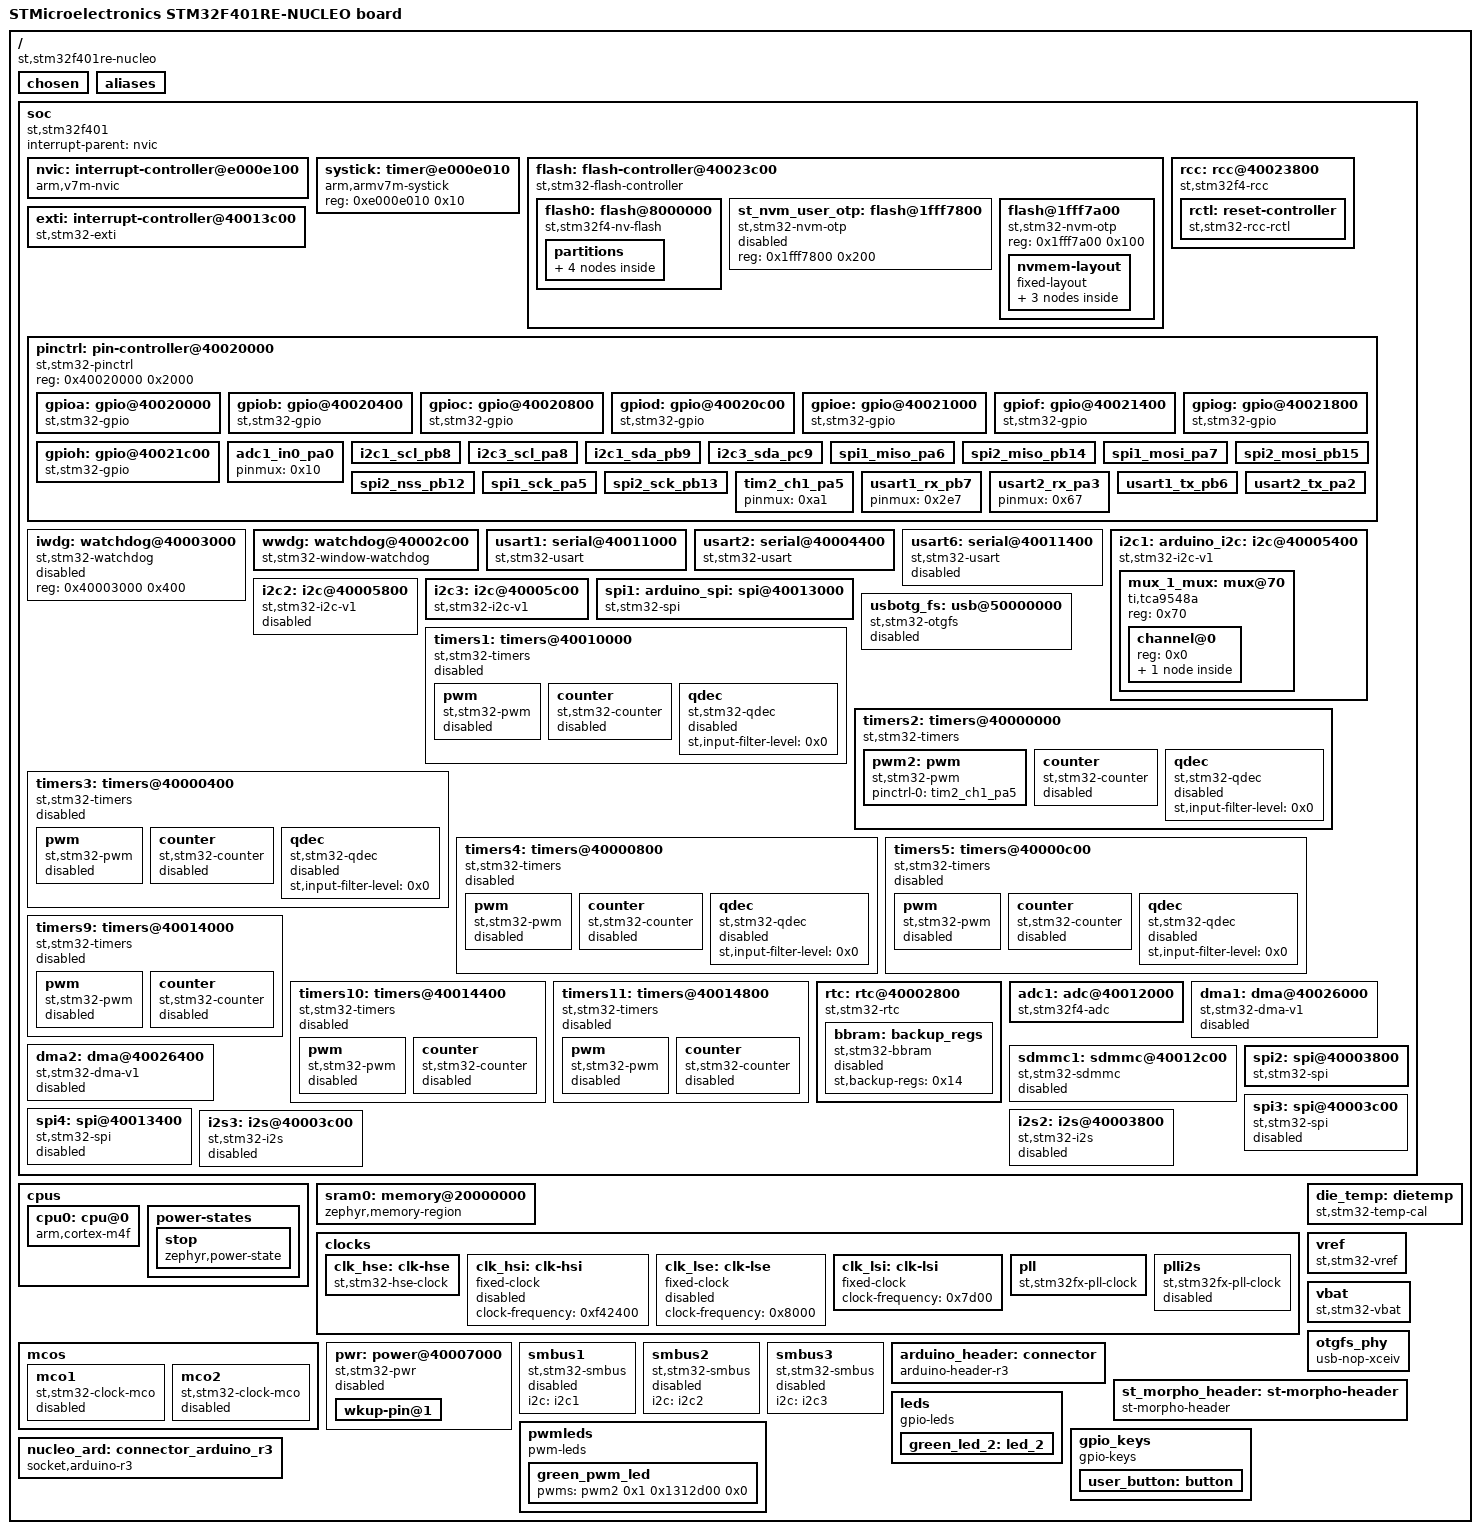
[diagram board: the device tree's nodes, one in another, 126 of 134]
/dts-v1/;

/* node '/' defined in zephyr/dts/common/skeleton.dtsi:9 */
/ {
	#address-cells = < 0x1 >;                              /* in zephyr/dts/common/skeleton.dtsi:10 */
	#size-cells = < 0x1 >;                                 /* in zephyr/dts/common/skeleton.dtsi:11 */
	model = "STMicroelectronics STM32F401RE-NUCLEO board"; /* in zephyr/boards/st/nucleo_f401re/nucleo_f401re.dts:16 */
	compatible = "st,stm32f401re-nucleo";                  /* in zephyr/boards/st/nucleo_f401re/nucleo_f401re.dts:17 */

	/* node '/chosen' defined in zephyr/dts/common/skeleton.dtsi:13 */
	chosen {
		zephyr,flash-controller = &flash;         /* in zephyr/dts/arm/st/f4/stm32f4.dtsi:26 */
		zephyr,system-timer-companion = &rtc;     /* in zephyr/dts/arm/st/f4/stm32f4.dtsi:27 */
		zephyr,console = &usart2;                 /* in zephyr/boards/st/nucleo_f401re/nucleo_f401re.dts:20 */
		zephyr,shell-uart = &usart2;              /* in zephyr/boards/st/nucleo_f401re/nucleo_f401re.dts:21 */
		zephyr,sram = &sram0;                     /* in zephyr/boards/st/nucleo_f401re/nucleo_f401re.dts:22 */
		zephyr,flash = &flash0;                   /* in zephyr/boards/st/nucleo_f401re/nucleo_f401re.dts:23 */
		zephyr,code-partition = &slot0_partition; /* in zephyr/boards/st/nucleo_f401re/nucleo_f401re.dts:24 */
	};

	/* node '/aliases' defined in zephyr/dts/common/skeleton.dtsi:15 */
	aliases {
		led0 = &green_led_2;       /* in zephyr/boards/st/nucleo_f401re/nucleo_f401re.dts:55 */
		sw0 = &user_button;        /* in zephyr/boards/st/nucleo_f401re/nucleo_f401re.dts:56 */
		pwm-led0 = &green_pwm_led; /* in zephyr/boards/st/nucleo_f401re/nucleo_f401re.dts:57 */
		watchdog0 = &wwdg;         /* in zephyr/boards/st/nucleo_f401re/nucleo_f401re.dts:58 */
		die-temp0 = &die_temp;     /* in zephyr/boards/st/nucleo_f401re/nucleo_f401re.dts:59 */
		rtc = &rtc;                /* in zephyr/boards/st/nucleo_f401re/nucleo_f401re.dts:60 */
		volt-sensor0 = &vref;      /* in zephyr/boards/st/nucleo_f401re/nucleo_f401re.dts:61 */
		volt-sensor1 = &vbat;      /* in zephyr/boards/st/nucleo_f401re/nucleo_f401re.dts:62 */
	};

	/* node '/soc' defined in zephyr/dts/arm/armv7-m.dtsi:6 */
	soc {
		#address-cells = < 0x1 >;     /* in zephyr/dts/arm/armv7-m.dtsi:7 */
		#size-cells = < 0x1 >;        /* in zephyr/dts/arm/armv7-m.dtsi:8 */
		interrupt-parent = < &nvic >; /* in zephyr/dts/arm/armv7-m.dtsi:10 */
		ranges;                       /* in zephyr/dts/arm/armv7-m.dtsi:11 */
		compatible = "st,stm32f401",
		             "st,stm32f4",
		             "simple-bus";    /* in zephyr/dts/arm/st/f4/stm32f401.dtsi:19 */

		/* node '/soc/interrupt-controller@e000e100' defined in zephyr/dts/arm/armv7-m.dtsi:13 */
		nvic: interrupt-controller@e000e100 {
			#address-cells = < 0x1 >;            /* in zephyr/dts/arm/armv7-m.dtsi:14 */
			compatible = "arm,v7m-nvic";         /* in zephyr/dts/arm/armv7-m.dtsi:15 */
			reg = < 0xe000e100 0xc00 >;          /* in zephyr/dts/arm/armv7-m.dtsi:16 */
			interrupt-controller;                /* in zephyr/dts/arm/armv7-m.dtsi:17 */
			#interrupt-cells = < 0x2 >;          /* in zephyr/dts/arm/armv7-m.dtsi:18 */
			arm,num-irq-priority-bits = < 0x4 >; /* in zephyr/dts/arm/st/f4/stm32f4.dtsi:730 */
			phandle = < 0x1 >;                   /* in zephyr/dts/arm/armv7-m.dtsi:10 */
		};

		/* node '/soc/timer@e000e010' defined in zephyr/dts/arm/armv7-m.dtsi:21 */
		systick: timer@e000e010 {
			compatible = "arm,armv7m-systick"; /* in zephyr/dts/arm/armv7-m.dtsi:22 */
			reg = < 0xe000e010 0x10 >;         /* in zephyr/dts/arm/armv7-m.dtsi:23 */
		};

		/* node '/soc/flash-controller@40023c00' defined in zephyr/dts/arm/st/f4/stm32f4.dtsi:112 */
		flash: flash-controller@40023c00 {
			compatible = "st,stm32-flash-controller",
			             "st,stm32f4-flash-controller"; /* in zephyr/dts/arm/st/f4/stm32f4.dtsi:113 */
			reg = < 0x40023c00 0x400 >;                 /* in zephyr/dts/arm/st/f4/stm32f4.dtsi:114 */
			interrupts = < 0x4 0x0 >;                   /* in zephyr/dts/arm/st/f4/stm32f4.dtsi:115 */
			#address-cells = < 0x1 >;                   /* in zephyr/dts/arm/st/f4/stm32f4.dtsi:117 */
			#size-cells = < 0x1 >;                      /* in zephyr/dts/arm/st/f4/stm32f4.dtsi:118 */
			ranges;                                     /* in zephyr/dts/arm/st/f4/stm32f4.dtsi:119 */

			/* node '/soc/flash-controller@40023c00/flash@8000000' defined in zephyr/dts/arm/st/f4/stm32f4.dtsi:121 */
			flash0: flash@8000000 {
				compatible = "st,stm32f4-nv-flash",
				             "st,stm32-nv-flash",
				             "soc-nv-flash";        /* in zephyr/dts/arm/st/f4/stm32f4.dtsi:122 */
				#address-cells = < 0x1 >;           /* in zephyr/dts/arm/st/f4/stm32f4.dtsi:124 */
				#size-cells = < 0x1 >;              /* in zephyr/dts/arm/st/f4/stm32f4.dtsi:125 */
				write-block-size = < 0x1 >;         /* in zephyr/dts/arm/st/f4/stm32f4.dtsi:126 */
				max-erase-time = < 0xfa0 >;         /* in zephyr/dts/arm/st/f4/stm32f4.dtsi:128 */
				reg = < 0x8000000 0x80000 >;        /* in zephyr/dts/arm/st/f4/stm32f401Xe.dtsi:17 */
				ranges = < 0x0 0x8000000 0x80000 >; /* in zephyr/dts/arm/st/f4/stm32f401Xe.dtsi:18 */

				/* node '/soc/flash-controller@40023c00/flash@8000000/partitions' defined in zephyr/boards/st/nucleo_f401re/nucleo_f401re.dts:140 */
				partitions {
					#address-cells = < 0x1 >; /* in zephyr/boards/st/nucleo_f401re/nucleo_f401re.dts:141 */
					#size-cells = < 0x1 >;    /* in zephyr/boards/st/nucleo_f401re/nucleo_f401re.dts:142 */
					ranges;                   /* in zephyr/boards/st/nucleo_f401re/nucleo_f401re.dts:143 */

					/* node '/soc/flash-controller@40023c00/flash@8000000/partitions/partition@0' defined in zephyr/boards/st/nucleo_f401re/nucleo_f401re.dts:145 */
					boot_partition: partition@0 {
						compatible = "zephyr,mapped-partition"; /* in zephyr/boards/st/nucleo_f401re/nucleo_f401re.dts:146 */
						label = "mcuboot";                      /* in zephyr/boards/st/nucleo_f401re/nucleo_f401re.dts:147 */
						reg = < 0x0 0x10000 >;                  /* in zephyr/boards/st/nucleo_f401re/nucleo_f401re.dts:148 */
						read-only;                              /* in zephyr/boards/st/nucleo_f401re/nucleo_f401re.dts:149 */
					};

					/* node '/soc/flash-controller@40023c00/flash@8000000/partitions/partition@20000' defined in zephyr/boards/st/nucleo_f401re/nucleo_f401re.dts:157 */
					slot0_partition: partition@20000 {
						compatible = "zephyr,mapped-partition"; /* in zephyr/boards/st/nucleo_f401re/nucleo_f401re.dts:158 */
						label = "image-0";                      /* in zephyr/boards/st/nucleo_f401re/nucleo_f401re.dts:159 */
						reg = < 0x20000 0x20000 >;              /* in zephyr/boards/st/nucleo_f401re/nucleo_f401re.dts:160 */
					};

					/* node '/soc/flash-controller@40023c00/flash@8000000/partitions/partition@40000' defined in zephyr/boards/st/nucleo_f401re/nucleo_f401re.dts:163 */
					slot1_partition: partition@40000 {
						compatible = "zephyr,mapped-partition"; /* in zephyr/boards/st/nucleo_f401re/nucleo_f401re.dts:164 */
						label = "image-1";                      /* in zephyr/boards/st/nucleo_f401re/nucleo_f401re.dts:165 */
						reg = < 0x40000 0x20000 >;              /* in zephyr/boards/st/nucleo_f401re/nucleo_f401re.dts:166 */
					};

					/* node '/soc/flash-controller@40023c00/flash@8000000/partitions/partition@60000' defined in zephyr/boards/st/nucleo_f401re/nucleo_f401re.dts:169 */
					scratch_partition: partition@60000 {
						compatible = "zephyr,mapped-partition"; /* in zephyr/boards/st/nucleo_f401re/nucleo_f401re.dts:170 */
						label = "image-scratch";                /* in zephyr/boards/st/nucleo_f401re/nucleo_f401re.dts:171 */
						reg = < 0x60000 0x20000 >;              /* in zephyr/boards/st/nucleo_f401re/nucleo_f401re.dts:172 */
					};
				};
			};

			/* node '/soc/flash-controller@40023c00/flash@1fff7800' defined in zephyr/dts/arm/st/f4/stm32f4.dtsi:131 */
			st_nvm_user_otp: flash@1fff7800 {
				compatible = "st,stm32-nvm-otp"; /* in zephyr/dts/arm/st/f4/stm32f4.dtsi:132 */
				reg = < 0x1fff7800 0x200 >;      /* in zephyr/dts/arm/st/f4/stm32f4.dtsi:133 */
				status = "disabled";             /* in zephyr/dts/arm/st/f4/stm32f4.dtsi:134 */
			};

			/* node '/soc/flash-controller@40023c00/flash@1fff7a00' defined in zephyr/dts/arm/st/f4/stm32f4.dtsi:148 */
			flash@1fff7a00 {
				compatible = "st,stm32-nvm-otp"; /* in zephyr/dts/arm/st/f4/stm32f4.dtsi:149 */
				reg = < 0x1fff7a00 0x100 >;      /* in zephyr/dts/arm/st/f4/stm32f4.dtsi:150 */

				/* node '/soc/flash-controller@40023c00/flash@1fff7a00/nvmem-layout' defined in zephyr/dts/arm/st/f4/stm32f4.dtsi:152 */
				nvmem-layout {
					compatible = "fixed-layout"; /* in zephyr/dts/arm/st/f4/stm32f4.dtsi:153 */
					#address-cells = < 0x1 >;    /* in zephyr/dts/arm/st/f4/stm32f4.dtsi:154 */
					#size-cells = < 0x1 >;       /* in zephyr/dts/arm/st/f4/stm32f4.dtsi:155 */

					/* node '/soc/flash-controller@40023c00/flash@1fff7a00/nvmem-layout/vrefint@2a' defined in zephyr/dts/arm/st/f4/stm32f4.dtsi:157 */
					vrefint_otp: vrefint@2a {
						reg = < 0x2a 0x2 >;          /* in zephyr/dts/arm/st/f4/stm32f4.dtsi:158 */
						#nvmem-cell-cells = < 0x0 >; /* in zephyr/dts/arm/st/f4/stm32f4.dtsi:159 */
						read-only;                   /* in zephyr/dts/arm/st/f4/stm32f4.dtsi:160 */
						phandle = < 0x20 >;          /* in zephyr/dts/arm/st/f4/stm32f4.dtsi:686 */
					};

					/* node '/soc/flash-controller@40023c00/flash@1fff7a00/nvmem-layout/ts-cal1@2c' defined in zephyr/dts/arm/st/f4/stm32f4.dtsi:163 */
					ts_cal1_otp: ts-cal1@2c {
						reg = < 0x2c 0x2 >;          /* in zephyr/dts/arm/st/f4/stm32f4.dtsi:164 */
						#nvmem-cell-cells = < 0x0 >; /* in zephyr/dts/arm/st/f4/stm32f4.dtsi:165 */
						read-only;                   /* in zephyr/dts/arm/st/f4/stm32f4.dtsi:166 */
						phandle = < 0x1d >;          /* in zephyr/dts/arm/st/f4/stm32f4.dtsi:675 */
					};

					/* node '/soc/flash-controller@40023c00/flash@1fff7a00/nvmem-layout/ts-cal2@2e' defined in zephyr/dts/arm/st/f4/stm32f4.dtsi:169 */
					ts_cal2_otp: ts-cal2@2e {
						reg = < 0x2e 0x2 >;          /* in zephyr/dts/arm/st/f4/stm32f4.dtsi:170 */
						#nvmem-cell-cells = < 0x0 >; /* in zephyr/dts/arm/st/f4/stm32f4.dtsi:171 */
						read-only;                   /* in zephyr/dts/arm/st/f4/stm32f4.dtsi:172 */
						phandle = < 0x1e >;          /* in zephyr/dts/arm/st/f4/stm32f4.dtsi:675 */
					};
				};
			};
		};

		/* node '/soc/rcc@40023800' defined in zephyr/dts/arm/st/f4/stm32f4.dtsi:178 */
		rcc: rcc@40023800 {
			compatible = "st,stm32f4-rcc";   /* in zephyr/dts/arm/st/f4/stm32f4.dtsi:179 */
			#clock-cells = < 0x2 >;          /* in zephyr/dts/arm/st/f4/stm32f4.dtsi:180 */
			reg = < 0x40023800 0x400 >;      /* in zephyr/dts/arm/st/f4/stm32f4.dtsi:181 */
			clocks = < &pll >;               /* in zephyr/boards/st/nucleo_f401re/nucleo_f401re.dts:86 */
			clock-frequency = < 0x501bd00 >; /* in zephyr/boards/st/nucleo_f401re/nucleo_f401re.dts:87 */
			ahb-prescaler = < 0x1 >;         /* in zephyr/boards/st/nucleo_f401re/nucleo_f401re.dts:88 */
			apb1-prescaler = < 0x2 >;        /* in zephyr/boards/st/nucleo_f401re/nucleo_f401re.dts:89 */
			apb2-prescaler = < 0x1 >;        /* in zephyr/boards/st/nucleo_f401re/nucleo_f401re.dts:90 */
			phandle = < 0x3 >;               /* in zephyr/dts/arm/st/f4/stm32f4.dtsi:195 */

			/* node '/soc/rcc@40023800/reset-controller' defined in zephyr/dts/arm/st/f4/stm32f4.dtsi:183 */
			rctl: reset-controller {
				compatible = "st,stm32-rcc-rctl"; /* in zephyr/dts/arm/st/f4/stm32f4.dtsi:184 */
				#reset-cells = < 0x1 >;           /* in zephyr/dts/arm/st/f4/stm32f4.dtsi:185 */
				phandle = < 0x4 >;                /* in zephyr/dts/arm/st/f4/stm32f4.dtsi:295 */
			};
		};

		/* node '/soc/interrupt-controller@40013c00' defined in zephyr/dts/arm/st/f4/stm32f4.dtsi:189 */
		exti: interrupt-controller@40013c00 {
			compatible = "st,stm32-exti";  /* in zephyr/dts/arm/st/f4/stm32f4.dtsi:190 */
			interrupt-controller;          /* in zephyr/dts/arm/st/f4/stm32f4.dtsi:191 */
			#interrupt-cells = < 0x1 >;    /* in zephyr/dts/arm/st/f4/stm32f4.dtsi:192 */
			#address-cells = < 0x0 >;      /* in zephyr/dts/arm/st/f4/stm32f4.dtsi:193 */
			reg = < 0x40013c00 0x400 >;    /* in zephyr/dts/arm/st/f4/stm32f4.dtsi:194 */
			clocks = < &rcc 0x44 0x4000 >; /* in zephyr/dts/arm/st/f4/stm32f4.dtsi:195 */
			num-lines = < 0x20 >;          /* in zephyr/dts/arm/st/f4/stm32f4.dtsi:196 */
			interrupts = < 0x6 0x0 >,
			             < 0x7 0x0 >,
			             < 0x8 0x0 >,
			             < 0x9 0x0 >,
			             < 0xa 0x0 >,
			             < 0x17 0x0 >,
			             < 0x28 0x0 >;     /* in zephyr/dts/arm/st/f4/stm32f4.dtsi:197 */
			interrupt-names = "line0",
			                  "line1",
			                  "line2",
			                  "line3",
			                  "line4",
			                  "line5-9",
			                  "line10-15"; /* in zephyr/dts/arm/st/f4/stm32f4.dtsi:199 */
			line-ranges = < 0x0 0x1 >,
			              < 0x1 0x1 >,
			              < 0x2 0x1 >,
			              < 0x3 0x1 >,
			              < 0x4 0x1 >,
			              < 0x5 0x5 >,
			              < 0xa 0x6 >;     /* in zephyr/dts/arm/st/f4/stm32f4.dtsi:201 */
		};

		/* node '/soc/pin-controller@40020000' defined in zephyr/dts/arm/st/f4/stm32f4.dtsi:205 */
		pinctrl: pin-controller@40020000 {
			compatible = "st,stm32-pinctrl"; /* in zephyr/dts/arm/st/f4/stm32f4.dtsi:206 */
			#address-cells = < 0x1 >;        /* in zephyr/dts/arm/st/f4/stm32f4.dtsi:207 */
			#size-cells = < 0x1 >;           /* in zephyr/dts/arm/st/f4/stm32f4.dtsi:208 */
			reg = < 0x40020000 0x2000 >;     /* in zephyr/dts/arm/st/f4/stm32f4.dtsi:209 */
			ranges;                          /* in zephyr/dts/arm/st/f4/stm32f4.dtsi:210 */

			/* node '/soc/pin-controller@40020000/gpio@40020000' defined in zephyr/dts/arm/st/f4/stm32f4.dtsi:212 */
			gpioa: gpio@40020000 {
				compatible = "st,stm32-gpio"; /* in zephyr/dts/arm/st/f4/stm32f4.dtsi:213 */
				gpio-controller;              /* in zephyr/dts/arm/st/f4/stm32f4.dtsi:214 */
				#gpio-cells = < 0x2 >;        /* in zephyr/dts/arm/st/f4/stm32f4.dtsi:215 */
				reg = < 0x40020000 0x400 >;   /* in zephyr/dts/arm/st/f4/stm32f4.dtsi:216 */
				clocks = < &rcc 0x30 0x1 >;   /* in zephyr/dts/arm/st/f4/stm32f4.dtsi:217 */
				phandle = < 0xe >;            /* in zephyr/boards/st/nucleo_f401re/nucleo_f401re.dts:119 */
			};

			/* node '/soc/pin-controller@40020000/gpio@40020400' defined in zephyr/dts/arm/st/f4/stm32f4.dtsi:220 */
			gpiob: gpio@40020400 {
				compatible = "st,stm32-gpio"; /* in zephyr/dts/arm/st/f4/stm32f4.dtsi:221 */
				gpio-controller;              /* in zephyr/dts/arm/st/f4/stm32f4.dtsi:222 */
				#gpio-cells = < 0x2 >;        /* in zephyr/dts/arm/st/f4/stm32f4.dtsi:223 */
				reg = < 0x40020400 0x400 >;   /* in zephyr/dts/arm/st/f4/stm32f4.dtsi:224 */
				clocks = < &rcc 0x30 0x2 >;   /* in zephyr/dts/arm/st/f4/stm32f4.dtsi:225 */
				phandle = < 0xb >;            /* in zephyr/boards/st/nucleo_f401re/nucleo_f401re.dts:110 */
			};

			/* node '/soc/pin-controller@40020000/gpio@40020800' defined in zephyr/dts/arm/st/f4/stm32f4.dtsi:228 */
			gpioc: gpio@40020800 {
				compatible = "st,stm32-gpio"; /* in zephyr/dts/arm/st/f4/stm32f4.dtsi:229 */
				gpio-controller;              /* in zephyr/dts/arm/st/f4/stm32f4.dtsi:230 */
				#gpio-cells = < 0x2 >;        /* in zephyr/dts/arm/st/f4/stm32f4.dtsi:231 */
				reg = < 0x40020800 0x400 >;   /* in zephyr/dts/arm/st/f4/stm32f4.dtsi:232 */
				clocks = < &rcc 0x30 0x4 >;   /* in zephyr/dts/arm/st/f4/stm32f4.dtsi:233 */
				phandle = < 0xf >;            /* in zephyr/boards/st/nucleo_f401re/nucleo_f401re.dts:120 */
			};

			/* node '/soc/pin-controller@40020000/gpio@40020c00' defined in zephyr/dts/arm/st/f4/stm32f4.dtsi:236 */
			gpiod: gpio@40020c00 {
				compatible = "st,stm32-gpio"; /* in zephyr/dts/arm/st/f4/stm32f4.dtsi:237 */
				gpio-controller;              /* in zephyr/dts/arm/st/f4/stm32f4.dtsi:238 */
				#gpio-cells = < 0x2 >;        /* in zephyr/dts/arm/st/f4/stm32f4.dtsi:239 */
				reg = < 0x40020c00 0x400 >;   /* in zephyr/dts/arm/st/f4/stm32f4.dtsi:240 */
				clocks = < &rcc 0x30 0x8 >;   /* in zephyr/dts/arm/st/f4/stm32f4.dtsi:241 */
				phandle = < 0x24 >;           /* in zephyr/boards/st/nucleo_f401re/st_morpho_connector.dtsi:15 */
			};

			/* node '/soc/pin-controller@40020000/gpio@40021000' defined in zephyr/dts/arm/st/f4/stm32f4.dtsi:244 */
			gpioe: gpio@40021000 {
				compatible = "st,stm32-gpio"; /* in zephyr/dts/arm/st/f4/stm32f4.dtsi:245 */
				gpio-controller;              /* in zephyr/dts/arm/st/f4/stm32f4.dtsi:246 */
				#gpio-cells = < 0x2 >;        /* in zephyr/dts/arm/st/f4/stm32f4.dtsi:247 */
				reg = < 0x40021000 0x400 >;   /* in zephyr/dts/arm/st/f4/stm32f4.dtsi:248 */
				clocks = < &rcc 0x30 0x10 >;  /* in zephyr/dts/arm/st/f4/stm32f4.dtsi:249 */
			};

			/* node '/soc/pin-controller@40020000/gpio@40021400' defined in zephyr/dts/arm/st/f4/stm32f4.dtsi:252 */
			gpiof: gpio@40021400 {
				compatible = "st,stm32-gpio"; /* in zephyr/dts/arm/st/f4/stm32f4.dtsi:253 */
				gpio-controller;              /* in zephyr/dts/arm/st/f4/stm32f4.dtsi:254 */
				#gpio-cells = < 0x2 >;        /* in zephyr/dts/arm/st/f4/stm32f4.dtsi:255 */
				reg = < 0x40021400 0x400 >;   /* in zephyr/dts/arm/st/f4/stm32f4.dtsi:256 */
				clocks = < &rcc 0x30 0x20 >;  /* in zephyr/dts/arm/st/f4/stm32f4.dtsi:257 */
			};

			/* node '/soc/pin-controller@40020000/gpio@40021800' defined in zephyr/dts/arm/st/f4/stm32f4.dtsi:260 */
			gpiog: gpio@40021800 {
				compatible = "st,stm32-gpio"; /* in zephyr/dts/arm/st/f4/stm32f4.dtsi:261 */
				gpio-controller;              /* in zephyr/dts/arm/st/f4/stm32f4.dtsi:262 */
				#gpio-cells = < 0x2 >;        /* in zephyr/dts/arm/st/f4/stm32f4.dtsi:263 */
				reg = < 0x40021800 0x400 >;   /* in zephyr/dts/arm/st/f4/stm32f4.dtsi:264 */
				clocks = < &rcc 0x30 0x40 >;  /* in zephyr/dts/arm/st/f4/stm32f4.dtsi:265 */
			};

			/* node '/soc/pin-controller@40020000/gpio@40021c00' defined in zephyr/dts/arm/st/f4/stm32f4.dtsi:268 */
			gpioh: gpio@40021c00 {
				compatible = "st,stm32-gpio"; /* in zephyr/dts/arm/st/f4/stm32f4.dtsi:269 */
				gpio-controller;              /* in zephyr/dts/arm/st/f4/stm32f4.dtsi:270 */
				#gpio-cells = < 0x2 >;        /* in zephyr/dts/arm/st/f4/stm32f4.dtsi:271 */
				reg = < 0x40021c00 0x400 >;   /* in zephyr/dts/arm/st/f4/stm32f4.dtsi:272 */
				clocks = < &rcc 0x30 0x80 >;  /* in zephyr/dts/arm/st/f4/stm32f4.dtsi:273 */
				phandle = < 0x25 >;           /* in zephyr/boards/st/nucleo_f401re/st_morpho_connector.dtsi:15 */
			};

			/* node '/soc/pin-controller@40020000/adc1_in0_pa0' defined in modules/hal/stm32/dts/st/f4/stm32f401r(d-e)tx-pinctrl.dtsi:13 */
			adc1_in0_pa0: adc1_in0_pa0 {
				pinmux = < 0x10 >;  /* in modules/hal/stm32/dts/st/f4/stm32f401r(d-e)tx-pinctrl.dtsi:14 */
				phandle = < 0x15 >; /* in zephyr/boards/st/nucleo_f401re/nucleo_f401re.dts:194 */
			};

			/* node '/soc/pin-controller@40020000/i2c1_scl_pb8' defined in modules/hal/stm32/dts/st/f4/stm32f401r(d-e)tx-pinctrl.dtsi:287 */
			i2c1_scl_pb8: i2c1_scl_pb8 {
				pinmux = < 0x304 >; /* in modules/hal/stm32/dts/st/f4/stm32f401r(d-e)tx-pinctrl.dtsi:288 */
				bias-pull-up;       /* in modules/hal/stm32/dts/st/f4/stm32f401r(d-e)tx-pinctrl.dtsi:289 */
				drive-open-drain;   /* in modules/hal/stm32/dts/st/f4/stm32f401r(d-e)tx-pinctrl.dtsi:290 */
				phandle = < 0x9 >;  /* in zephyr/boards/st/nucleo_f401re/nucleo_f401re.dts:108 */
			};

			/* node '/soc/pin-controller@40020000/i2c3_scl_pa8' defined in modules/hal/stm32/dts/st/f4/stm32f401r(d-e)tx-pinctrl.dtsi:299 */
			i2c3_scl_pa8: i2c3_scl_pa8 {
				pinmux = < 0x104 >; /* in modules/hal/stm32/dts/st/f4/stm32f401r(d-e)tx-pinctrl.dtsi:300 */
				bias-pull-up;       /* in modules/hal/stm32/dts/st/f4/stm32f401r(d-e)tx-pinctrl.dtsi:301 */
				drive-open-drain;   /* in modules/hal/stm32/dts/st/f4/stm32f401r(d-e)tx-pinctrl.dtsi:302 */
				phandle = < 0xc >;  /* in zephyr/boards/st/nucleo_f401re/nucleo_f401re.dts:117 */
			};

			/* node '/soc/pin-controller@40020000/i2c1_sda_pb9' defined in modules/hal/stm32/dts/st/f4/stm32f401r(d-e)tx-pinctrl.dtsi:313 */
			i2c1_sda_pb9: i2c1_sda_pb9 {
				pinmux = < 0x324 >; /* in modules/hal/stm32/dts/st/f4/stm32f401r(d-e)tx-pinctrl.dtsi:314 */
				bias-pull-up;       /* in modules/hal/stm32/dts/st/f4/stm32f401r(d-e)tx-pinctrl.dtsi:315 */
				drive-open-drain;   /* in modules/hal/stm32/dts/st/f4/stm32f401r(d-e)tx-pinctrl.dtsi:316 */
				phandle = < 0xa >;  /* in zephyr/boards/st/nucleo_f401re/nucleo_f401re.dts:108 */
			};

			/* node '/soc/pin-controller@40020000/i2c3_sda_pc9' defined in modules/hal/stm32/dts/st/f4/stm32f401r(d-e)tx-pinctrl.dtsi:331 */
			i2c3_sda_pc9: i2c3_sda_pc9 {
				pinmux = < 0x524 >; /* in modules/hal/stm32/dts/st/f4/stm32f401r(d-e)tx-pinctrl.dtsi:332 */
				bias-pull-up;       /* in modules/hal/stm32/dts/st/f4/stm32f401r(d-e)tx-pinctrl.dtsi:333 */
				drive-open-drain;   /* in modules/hal/stm32/dts/st/f4/stm32f401r(d-e)tx-pinctrl.dtsi:334 */
				phandle = < 0xd >;  /* in zephyr/boards/st/nucleo_f401re/nucleo_f401re.dts:117 */
			};

			/* node '/soc/pin-controller@40020000/spi1_miso_pa6' defined in modules/hal/stm32/dts/st/f4/stm32f401r(d-e)tx-pinctrl.dtsi:522 */
			spi1_miso_pa6: spi1_miso_pa6 {
				pinmux = < 0xc5 >;             /* in modules/hal/stm32/dts/st/f4/stm32f401r(d-e)tx-pinctrl.dtsi:523 */
				bias-pull-down;                /* in modules/hal/stm32/dts/st/f4/stm32f401r(d-e)tx-pinctrl.dtsi:524 */
				slew-rate = "very-high-speed"; /* in modules/hal/stm32/dts/st/f4/stm32f401r(d-e)tx-pinctrl.dtsi:525 */
				phandle = < 0x11 >;            /* in zephyr/boards/st/nucleo_f401re/nucleo_f401re.dts:126 */
			};

			/* node '/soc/pin-controller@40020000/spi2_miso_pb14' defined in modules/hal/stm32/dts/st/f4/stm32f401r(d-e)tx-pinctrl.dtsi:534 */
			spi2_miso_pb14: spi2_miso_pb14 {
				pinmux = < 0x3c5 >;            /* in modules/hal/stm32/dts/st/f4/stm32f401r(d-e)tx-pinctrl.dtsi:535 */
				bias-pull-down;                /* in modules/hal/stm32/dts/st/f4/stm32f401r(d-e)tx-pinctrl.dtsi:536 */
				slew-rate = "very-high-speed"; /* in modules/hal/stm32/dts/st/f4/stm32f401r(d-e)tx-pinctrl.dtsi:537 */
				phandle = < 0x18 >;            /* in zephyr/boards/st/nucleo_f401re/nucleo_f401re.dts:133 */
			};

			/* node '/soc/pin-controller@40020000/spi1_mosi_pa7' defined in modules/hal/stm32/dts/st/f4/stm32f401r(d-e)tx-pinctrl.dtsi:560 */
			spi1_mosi_pa7: spi1_mosi_pa7 {
				pinmux = < 0xe5 >;             /* in modules/hal/stm32/dts/st/f4/stm32f401r(d-e)tx-pinctrl.dtsi:561 */
				bias-pull-down;                /* in modules/hal/stm32/dts/st/f4/stm32f401r(d-e)tx-pinctrl.dtsi:562 */
				slew-rate = "very-high-speed"; /* in modules/hal/stm32/dts/st/f4/stm32f401r(d-e)tx-pinctrl.dtsi:563 */
				phandle = < 0x12 >;            /* in zephyr/boards/st/nucleo_f401re/nucleo_f401re.dts:126 */
			};

			/* node '/soc/pin-controller@40020000/spi2_mosi_pb15' defined in modules/hal/stm32/dts/st/f4/stm32f401r(d-e)tx-pinctrl.dtsi:572 */
			spi2_mosi_pb15: spi2_mosi_pb15 {
				pinmux = < 0x3e5 >;            /* in modules/hal/stm32/dts/st/f4/stm32f401r(d-e)tx-pinctrl.dtsi:573 */
				bias-pull-down;                /* in modules/hal/stm32/dts/st/f4/stm32f401r(d-e)tx-pinctrl.dtsi:574 */
				slew-rate = "very-high-speed"; /* in modules/hal/stm32/dts/st/f4/stm32f401r(d-e)tx-pinctrl.dtsi:575 */
				phandle = < 0x19 >;            /* in zephyr/boards/st/nucleo_f401re/nucleo_f401re.dts:133 */
			};

			/* node '/soc/pin-controller@40020000/spi2_nss_pb12' defined in modules/hal/stm32/dts/st/f4/stm32f401r(d-e)tx-pinctrl.dtsi:616 */
			spi2_nss_pb12: spi2_nss_pb12 {
				pinmux = < 0x385 >;            /* in modules/hal/stm32/dts/st/f4/stm32f401r(d-e)tx-pinctrl.dtsi:617 */
				bias-pull-up;                  /* in modules/hal/stm32/dts/st/f4/stm32f401r(d-e)tx-pinctrl.dtsi:618 */
				slew-rate = "very-high-speed"; /* in modules/hal/stm32/dts/st/f4/stm32f401r(d-e)tx-pinctrl.dtsi:619 */
				phandle = < 0x16 >;            /* in zephyr/boards/st/nucleo_f401re/nucleo_f401re.dts:133 */
			};

			/* node '/soc/pin-controller@40020000/spi1_sck_pa5' defined in modules/hal/stm32/dts/st/f4/stm32f401r(d-e)tx-pinctrl.dtsi:636 */
			spi1_sck_pa5: spi1_sck_pa5 {
				pinmux = < 0xa5 >;             /* in modules/hal/stm32/dts/st/f4/stm32f401r(d-e)tx-pinctrl.dtsi:637 */
				bias-pull-down;                /* in modules/hal/stm32/dts/st/f4/stm32f401r(d-e)tx-pinctrl.dtsi:638 */
				slew-rate = "very-high-speed"; /* in modules/hal/stm32/dts/st/f4/stm32f401r(d-e)tx-pinctrl.dtsi:639 */
				phandle = < 0x10 >;            /* in zephyr/boards/st/nucleo_f401re/nucleo_f401re.dts:126 */
			};

			/* node '/soc/pin-controller@40020000/spi2_sck_pb13' defined in modules/hal/stm32/dts/st/f4/stm32f401r(d-e)tx-pinctrl.dtsi:654 */
			spi2_sck_pb13: spi2_sck_pb13 {
				pinmux = < 0x3a5 >;            /* in modules/hal/stm32/dts/st/f4/stm32f401r(d-e)tx-pinctrl.dtsi:655 */
				bias-pull-down;                /* in modules/hal/stm32/dts/st/f4/stm32f401r(d-e)tx-pinctrl.dtsi:656 */
				slew-rate = "very-high-speed"; /* in modules/hal/stm32/dts/st/f4/stm32f401r(d-e)tx-pinctrl.dtsi:657 */
				phandle = < 0x17 >;            /* in zephyr/boards/st/nucleo_f401re/nucleo_f401re.dts:133 */
			};

			/* node '/soc/pin-controller@40020000/tim2_ch1_pa5' defined in modules/hal/stm32/dts/st/f4/stm32f401r(d-e)tx-pinctrl.dtsi:748 */
			tim2_ch1_pa5: tim2_ch1_pa5 {
				pinmux = < 0xa1 >;  /* in modules/hal/stm32/dts/st/f4/stm32f401r(d-e)tx-pinctrl.dtsi:749 */
				phandle = < 0x14 >; /* in zephyr/boards/st/nucleo_f401re/nucleo_f401re.dts:182 */
			};

			/* node '/soc/pin-controller@40020000/usart1_rx_pb7' defined in modules/hal/stm32/dts/st/f4/stm32f401r(d-e)tx-pinctrl.dtsi:874 */
			usart1_rx_pb7: usart1_rx_pb7 {
				pinmux = < 0x2e7 >; /* in modules/hal/stm32/dts/st/f4/stm32f401r(d-e)tx-pinctrl.dtsi:875 */
				phandle = < 0x6 >;  /* in zephyr/boards/st/nucleo_f401re/nucleo_f401re.dts:94 */
			};

			/* node '/soc/pin-controller@40020000/usart2_rx_pa3' defined in modules/hal/stm32/dts/st/f4/stm32f401r(d-e)tx-pinctrl.dtsi:878 */
			usart2_rx_pa3: usart2_rx_pa3 {
				pinmux = < 0x67 >; /* in modules/hal/stm32/dts/st/f4/stm32f401r(d-e)tx-pinctrl.dtsi:879 */
				phandle = < 0x8 >; /* in zephyr/boards/st/nucleo_f401re/nucleo_f401re.dts:101 */
			};

			/* node '/soc/pin-controller@40020000/usart1_tx_pb6' defined in modules/hal/stm32/dts/st/f4/stm32f401r(d-e)tx-pinctrl.dtsi:897 */
			usart1_tx_pb6: usart1_tx_pb6 {
				pinmux = < 0x2c7 >; /* in modules/hal/stm32/dts/st/f4/stm32f401r(d-e)tx-pinctrl.dtsi:898 */
				bias-pull-up;       /* in modules/hal/stm32/dts/st/f4/stm32f401r(d-e)tx-pinctrl.dtsi:899 */
				phandle = < 0x5 >;  /* in zephyr/boards/st/nucleo_f401re/nucleo_f401re.dts:94 */
			};

			/* node '/soc/pin-controller@40020000/usart2_tx_pa2' defined in modules/hal/stm32/dts/st/f4/stm32f401r(d-e)tx-pinctrl.dtsi:902 */
			usart2_tx_pa2: usart2_tx_pa2 {
				pinmux = < 0x47 >; /* in modules/hal/stm32/dts/st/f4/stm32f401r(d-e)tx-pinctrl.dtsi:903 */
				bias-pull-up;      /* in modules/hal/stm32/dts/st/f4/stm32f401r(d-e)tx-pinctrl.dtsi:904 */
				phandle = < 0x7 >; /* in zephyr/boards/st/nucleo_f401re/nucleo_f401re.dts:101 */
			};
		};

		/* node '/soc/watchdog@40003000' defined in zephyr/dts/arm/st/f4/stm32f4.dtsi:277 */
		iwdg: watchdog@40003000 {
			compatible = "st,stm32-watchdog"; /* in zephyr/dts/arm/st/f4/stm32f4.dtsi:278 */
			reg = < 0x40003000 0x400 >;       /* in zephyr/dts/arm/st/f4/stm32f4.dtsi:279 */
			status = "disabled";              /* in zephyr/dts/arm/st/f4/stm32f4.dtsi:280 */
		};

		/* node '/soc/watchdog@40002c00' defined in zephyr/dts/arm/st/f4/stm32f4.dtsi:283 */
		wwdg: watchdog@40002c00 {
			compatible = "st,stm32-window-watchdog"; /* in zephyr/dts/arm/st/f4/stm32f4.dtsi:284 */
			reg = < 0x40002c00 0x400 >;              /* in zephyr/dts/arm/st/f4/stm32f4.dtsi:285 */
			clocks = < &rcc 0x40 0x800 >;            /* in zephyr/dts/arm/st/f4/stm32f4.dtsi:286 */
			interrupts = < 0x0 0x0 >;                /* in zephyr/dts/arm/st/f4/stm32f4.dtsi:287 */
			status = "okay";                         /* in zephyr/boards/st/nucleo_f401re/nucleo_f401re.dts:206 */
		};

		/* node '/soc/serial@40011000' defined in zephyr/dts/arm/st/f4/stm32f4.dtsi:291 */
		usart1: serial@40011000 {
			compatible = "st,stm32-usart",
			             "st,stm32-uart";                  /* in zephyr/dts/arm/st/f4/stm32f4.dtsi:292 */
			reg = < 0x40011000 0x400 >;                    /* in zephyr/dts/arm/st/f4/stm32f4.dtsi:293 */
			clocks = < &rcc 0x44 0x10 >;                   /* in zephyr/dts/arm/st/f4/stm32f4.dtsi:294 */
			resets = < &rctl 0x484 >;                      /* in zephyr/dts/arm/st/f4/stm32f4.dtsi:295 */
			interrupts = < 0x25 0x0 >;                     /* in zephyr/dts/arm/st/f4/stm32f4.dtsi:296 */
			pinctrl-0 = < &usart1_tx_pb6 &usart1_rx_pb7 >; /* in zephyr/boards/st/nucleo_f401re/nucleo_f401re.dts:94 */
			pinctrl-names = "default";                     /* in zephyr/boards/st/nucleo_f401re/nucleo_f401re.dts:95 */
			current-speed = < 0x1c200 >;                   /* in zephyr/boards/st/nucleo_f401re/nucleo_f401re.dts:96 */
			status = "okay";                               /* in zephyr/boards/st/nucleo_f401re/nucleo_f401re.dts:97 */
		};

		/* node '/soc/serial@40004400' defined in zephyr/dts/arm/st/f4/stm32f4.dtsi:300 */
		usart2: serial@40004400 {
			compatible = "st,stm32-usart",
			             "st,stm32-uart";                  /* in zephyr/dts/arm/st/f4/stm32f4.dtsi:301 */
			reg = < 0x40004400 0x400 >;                    /* in zephyr/dts/arm/st/f4/stm32f4.dtsi:302 */
			clocks = < &rcc 0x40 0x20000 >;                /* in zephyr/dts/arm/st/f4/stm32f4.dtsi:303 */
			resets = < &rctl 0x411 >;                      /* in zephyr/dts/arm/st/f4/stm32f4.dtsi:304 */
			interrupts = < 0x26 0x0 >;                     /* in zephyr/dts/arm/st/f4/stm32f4.dtsi:305 */
			pinctrl-0 = < &usart2_tx_pa2 &usart2_rx_pa3 >; /* in zephyr/boards/st/nucleo_f401re/nucleo_f401re.dts:101 */
			pinctrl-names = "default";                     /* in zephyr/boards/st/nucleo_f401re/nucleo_f401re.dts:102 */
			current-speed = < 0x1c200 >;                   /* in zephyr/boards/st/nucleo_f401re/nucleo_f401re.dts:103 */
			status = "okay";                               /* in zephyr/boards/st/nucleo_f401re/nucleo_f401re.dts:104 */
		};

		/* node '/soc/serial@40011400' defined in zephyr/dts/arm/st/f4/stm32f4.dtsi:309 */
		usart6: serial@40011400 {
			compatible = "st,stm32-usart",
			             "st,stm32-uart";  /* in zephyr/dts/arm/st/f4/stm32f4.dtsi:310 */
			reg = < 0x40011400 0x400 >;    /* in zephyr/dts/arm/st/f4/stm32f4.dtsi:311 */
			clocks = < &rcc 0x44 0x20 >;   /* in zephyr/dts/arm/st/f4/stm32f4.dtsi:312 */
			resets = < &rctl 0x485 >;      /* in zephyr/dts/arm/st/f4/stm32f4.dtsi:313 */
			interrupts = < 0x47 0x0 >;     /* in zephyr/dts/arm/st/f4/stm32f4.dtsi:314 */
			status = "disabled";           /* in zephyr/dts/arm/st/f4/stm32f4.dtsi:315 */
		};

		/* node '/soc/i2c@40005400' defined in zephyr/dts/arm/st/f4/stm32f4.dtsi:318 */
		i2c1: arduino_i2c: i2c@40005400 {
			compatible = "st,stm32-i2c-v1";              /* in zephyr/dts/arm/st/f4/stm32f4.dtsi:319 */
			#address-cells = < 0x1 >;                    /* in zephyr/dts/arm/st/f4/stm32f4.dtsi:321 */
			#size-cells = < 0x0 >;                       /* in zephyr/dts/arm/st/f4/stm32f4.dtsi:322 */
			reg = < 0x40005400 0x400 >;                  /* in zephyr/dts/arm/st/f4/stm32f4.dtsi:323 */
			clocks = < &rcc 0x40 0x200000 >;             /* in zephyr/dts/arm/st/f4/stm32f4.dtsi:324 */
			interrupts = < 0x1f 0x0 >,
			             < 0x20 0x0 >;                   /* in zephyr/dts/arm/st/f4/stm32f4.dtsi:325 */
			interrupt-names = "event",
			                  "error";                   /* in zephyr/dts/arm/st/f4/stm32f4.dtsi:326 */
			pinctrl-0 = < &i2c1_scl_pb8 &i2c1_sda_pb9 >; /* in zephyr/boards/st/nucleo_f401re/nucleo_f401re.dts:108 */
			pinctrl-names = "default";                   /* in zephyr/boards/st/nucleo_f401re/nucleo_f401re.dts:109 */
			scl-gpios = < &gpiob 0x8 0x0 >;              /* in zephyr/boards/st/nucleo_f401re/nucleo_f401re.dts:110 */
			sda-gpios = < &gpiob 0x9 0x0 >;              /* in zephyr/boards/st/nucleo_f401re/nucleo_f401re.dts:111 */
			status = "okay";                             /* in zephyr/boards/st/nucleo_f401re/nucleo_f401re.dts:112 */
			clock-frequency = < 0x61a80 >;               /* in zephyr/boards/st/nucleo_f401re/nucleo_f401re.dts:113 */
			phandle = < 0x21 >;                          /* in zephyr/dts/arm/st/f4/stm32f4.dtsi:708 */

			/* node '/soc/i2c@40005400/mux@70' defined in <RIGC_BUILD>/rig/rig-gen.overlay:6 */
			mux_1_mux: mux@70 {
				compatible = "ti,tca9548a"; /* in <RIGC_BUILD>/rig/rig-gen.overlay:7 */
				reg = < 0x70 >;             /* in <RIGC_BUILD>/rig/rig-gen.overlay:8 */
				#address-cells = < 0x1 >;   /* in <RIGC_BUILD>/rig/rig-gen.overlay:9 */
				#size-cells = < 0x0 >;      /* in <RIGC_BUILD>/rig/rig-gen.overlay:10 */

				/* node '/soc/i2c@40005400/mux@70/channel@0' defined in <RIGC_BUILD>/rig/rig-gen.overlay:11 */
				channel@0 {
					reg = < 0x0 >;            /* in <RIGC_BUILD>/rig/rig-gen.overlay:12 */
					#address-cells = < 0x1 >; /* in <RIGC_BUILD>/rig/rig-gen.overlay:13 */
					#size-cells = < 0x0 >;    /* in <RIGC_BUILD>/rig/rig-gen.overlay:14 */

					/* node '/soc/i2c@40005400/mux@70/channel@0/sensor@48' defined in <RIGC_BUILD>/rig/rig-gen.overlay:15 */
					sensor_0_sensor: sensor@48 {
						compatible = "vnd,temp0x48"; /* in <RIGC_BUILD>/rig/rig-gen.overlay:16 */
						reg = < 0x48 >;              /* in <RIGC_BUILD>/rig/rig-gen.overlay:17 */
						status = "okay";             /* in <RIGC_BUILD>/rig/rig-gen.overlay:18 */
					};
				};
			};
		};

		/* node '/soc/i2c@40005800' defined in zephyr/dts/arm/st/f4/stm32f4.dtsi:330 */
		i2c2: i2c@40005800 {
			compatible = "st,stm32-i2c-v1";  /* in zephyr/dts/arm/st/f4/stm32f4.dtsi:331 */
			clock-frequency = < 0x186a0 >;   /* in zephyr/dts/arm/st/f4/stm32f4.dtsi:332 */
			#address-cells = < 0x1 >;        /* in zephyr/dts/arm/st/f4/stm32f4.dtsi:333 */
			#size-cells = < 0x0 >;           /* in zephyr/dts/arm/st/f4/stm32f4.dtsi:334 */
			reg = < 0x40005800 0x400 >;      /* in zephyr/dts/arm/st/f4/stm32f4.dtsi:335 */
			clocks = < &rcc 0x40 0x400000 >; /* in zephyr/dts/arm/st/f4/stm32f4.dtsi:336 */
			interrupts = < 0x21 0x0 >,
			             < 0x22 0x0 >;       /* in zephyr/dts/arm/st/f4/stm32f4.dtsi:337 */
			interrupt-names = "event",
			                  "error";       /* in zephyr/dts/arm/st/f4/stm32f4.dtsi:338 */
			status = "disabled";             /* in zephyr/dts/arm/st/f4/stm32f4.dtsi:339 */
			phandle = < 0x22 >;              /* in zephyr/dts/arm/st/f4/stm32f4.dtsi:716 */
		};

		/* node '/soc/i2c@40005c00' defined in zephyr/dts/arm/st/f4/stm32f4.dtsi:342 */
		i2c3: i2c@40005c00 {
			compatible = "st,stm32-i2c-v1";              /* in zephyr/dts/arm/st/f4/stm32f4.dtsi:343 */
			#address-cells = < 0x1 >;                    /* in zephyr/dts/arm/st/f4/stm32f4.dtsi:345 */
			#size-cells = < 0x0 >;                       /* in zephyr/dts/arm/st/f4/stm32f4.dtsi:346 */
			reg = < 0x40005c00 0x400 >;                  /* in zephyr/dts/arm/st/f4/stm32f4.dtsi:347 */
			clocks = < &rcc 0x40 0x800000 >;             /* in zephyr/dts/arm/st/f4/stm32f4.dtsi:348 */
			interrupts = < 0x48 0x0 >,
			             < 0x49 0x0 >;                   /* in zephyr/dts/arm/st/f4/stm32f4.dtsi:349 */
			interrupt-names = "event",
			                  "error";                   /* in zephyr/dts/arm/st/f4/stm32f4.dtsi:350 */
			pinctrl-0 = < &i2c3_scl_pa8 &i2c3_sda_pc9 >; /* in zephyr/boards/st/nucleo_f401re/nucleo_f401re.dts:117 */
			pinctrl-names = "default";                   /* in zephyr/boards/st/nucleo_f401re/nucleo_f401re.dts:118 */
			scl-gpios = < &gpioa 0x8 0x0 >;              /* in zephyr/boards/st/nucleo_f401re/nucleo_f401re.dts:119 */
			sda-gpios = < &gpioc 0x9 0x0 >;              /* in zephyr/boards/st/nucleo_f401re/nucleo_f401re.dts:120 */
			status = "okay";                             /* in zephyr/boards/st/nucleo_f401re/nucleo_f401re.dts:121 */
			clock-frequency = < 0x61a80 >;               /* in zephyr/boards/st/nucleo_f401re/nucleo_f401re.dts:122 */
			phandle = < 0x23 >;                          /* in zephyr/dts/arm/st/f4/stm32f4.dtsi:724 */
		};

		/* node '/soc/spi@40013000' defined in zephyr/dts/arm/st/f4/stm32f4.dtsi:354 */
		spi1: arduino_spi: spi@40013000 {
			compatible = "st,stm32-spi";                                 /* in zephyr/dts/arm/st/f4/stm32f4.dtsi:355 */
			#address-cells = < 0x1 >;                                    /* in zephyr/dts/arm/st/f4/stm32f4.dtsi:356 */
			#size-cells = < 0x0 >;                                       /* in zephyr/dts/arm/st/f4/stm32f4.dtsi:357 */
			reg = < 0x40013000 0x400 >;                                  /* in zephyr/dts/arm/st/f4/stm32f4.dtsi:358 */
			clocks = < &rcc 0x44 0x1000 >;                               /* in zephyr/dts/arm/st/f4/stm32f4.dtsi:359 */
			interrupts = < 0x23 0x0 >;                                   /* in zephyr/dts/arm/st/f4/stm32f4.dtsi:360 */
			st,spi-data-width = "limited-8-16-bit";                      /* in zephyr/dts/arm/st/f4/stm32f4.dtsi:361 */
			pinctrl-0 = < &spi1_sck_pa5 &spi1_miso_pa6 &spi1_mosi_pa7 >; /* in zephyr/boards/st/nucleo_f401re/nucleo_f401re.dts:126 */
			pinctrl-names = "default";                                   /* in zephyr/boards/st/nucleo_f401re/nucleo_f401re.dts:127 */
			cs-gpios = < &gpiob 0x6 0x11 >;                              /* in zephyr/boards/st/nucleo_f401re/nucleo_f401re.dts:128 */
			status = "okay";                                             /* in zephyr/boards/st/nucleo_f401re/nucleo_f401re.dts:129 */
			phandle = < 0x27 >;                                          /* in btr-shields/boards/extend/st/nucleo_f401re/arduino_r3_socket.dtsi:55 */
		};

		/* node '/soc/usb@50000000' defined in zephyr/dts/arm/st/f4/stm32f4.dtsi:365 */
		usbotg_fs: usb@50000000 {
			compatible = "st,stm32-otgfs"; /* in zephyr/dts/arm/st/f4/stm32f4.dtsi:366 */
			reg = < 0x50000000 0x40000 >;  /* in zephyr/dts/arm/st/f4/stm32f4.dtsi:367 */
			interrupts = < 0x43 0x0 >;     /* in zephyr/dts/arm/st/f4/stm32f4.dtsi:368 */
			interrupt-names = "otgfs";     /* in zephyr/dts/arm/st/f4/stm32f4.dtsi:369 */
			num-bidir-endpoints = < 0x4 >; /* in zephyr/dts/arm/st/f4/stm32f4.dtsi:370 */
			ram-size = < 0x500 >;          /* in zephyr/dts/arm/st/f4/stm32f4.dtsi:371 */
			maximum-speed = "full-speed";  /* in zephyr/dts/arm/st/f4/stm32f4.dtsi:372 */
			phys = < &otgfs_phy >;         /* in zephyr/dts/arm/st/f4/stm32f4.dtsi:373 */
			clocks = < &rcc 0x34 0x80 >,
			         < &rcc 0x7 0xff >;    /* in zephyr/dts/arm/st/f4/stm32f4.dtsi:374 */
			status = "disabled";           /* in zephyr/dts/arm/st/f4/stm32f4.dtsi:376 */
		};

		/* node '/soc/timers@40010000' defined in zephyr/dts/arm/st/f4/stm32f4.dtsi:379 */
		timers1: timers@40010000 {
			compatible = "st,stm32-timers"; /* in zephyr/dts/arm/st/f4/stm32f4.dtsi:380 */
			reg = < 0x40010000 0x400 >;     /* in zephyr/dts/arm/st/f4/stm32f4.dtsi:381 */
			clocks = < &rcc 0x44 0x1 >,
			         < &rcc 0x16 0xff >;    /* in zephyr/dts/arm/st/f4/stm32f4.dtsi:382 */
			resets = < &rctl 0x480 >;       /* in zephyr/dts/arm/st/f4/stm32f4.dtsi:384 */
			interrupts = < 0x18 0x0 >,
			             < 0x19 0x0 >,
			             < 0x1a 0x0 >,
			             < 0x1b 0x0 >;      /* in zephyr/dts/arm/st/f4/stm32f4.dtsi:385 */
			interrupt-names = "brk",
			                  "up",
			                  "trgcom",
			                  "cc";         /* in zephyr/dts/arm/st/f4/stm32f4.dtsi:386 */
			st,prescaler = < 0x0 >;         /* in zephyr/dts/arm/st/f4/stm32f4.dtsi:387 */
			status = "disabled";            /* in zephyr/dts/arm/st/f4/stm32f4.dtsi:388 */

			/* node '/soc/timers@40010000/pwm' defined in zephyr/dts/arm/st/f4/stm32f4.dtsi:390 */
			pwm {
				compatible = "st,stm32-pwm"; /* in zephyr/dts/arm/st/f4/stm32f4.dtsi:391 */
				status = "disabled";         /* in zephyr/dts/arm/st/f4/stm32f4.dtsi:392 */
				#pwm-cells = < 0x3 >;        /* in zephyr/dts/arm/st/f4/stm32f4.dtsi:393 */
			};

			/* node '/soc/timers@40010000/counter' defined in zephyr/dts/arm/st/f4/stm32f4.dtsi:396 */
			counter {
				compatible = "st,stm32-counter"; /* in zephyr/dts/arm/st/f4/stm32f4.dtsi:397 */
				status = "disabled";             /* in zephyr/dts/arm/st/f4/stm32f4.dtsi:398 */
			};

			/* node '/soc/timers@40010000/qdec' defined in zephyr/dts/arm/st/f4/stm32f4.dtsi:401 */
			qdec {
				compatible = "st,stm32-qdec";    /* in zephyr/dts/arm/st/f4/stm32f4.dtsi:402 */
				st,input-filter-level = < 0x0 >; /* in zephyr/dts/arm/st/f4/stm32f4.dtsi:403 */
				status = "disabled";             /* in zephyr/dts/arm/st/f4/stm32f4.dtsi:404 */
			};
		};

		/* node '/soc/timers@40000000' defined in zephyr/dts/arm/st/f4/stm32f4.dtsi:408 */
		timers2: timers@40000000 {
			compatible = "st,stm32-timers"; /* in zephyr/dts/arm/st/f4/stm32f4.dtsi:409 */
			reg = < 0x40000000 0x400 >;     /* in zephyr/dts/arm/st/f4/stm32f4.dtsi:410 */
			clocks = < &rcc 0x40 0x1 >,
			         < &rcc 0x15 0xff >;    /* in zephyr/dts/arm/st/f4/stm32f4.dtsi:411 */
			resets = < &rctl 0x400 >;       /* in zephyr/dts/arm/st/f4/stm32f4.dtsi:413 */
			interrupts = < 0x1c 0x0 >;      /* in zephyr/dts/arm/st/f4/stm32f4.dtsi:414 */
			interrupt-names = "global";     /* in zephyr/dts/arm/st/f4/stm32f4.dtsi:415 */
			st,prescaler = < 0x0 >;         /* in zephyr/dts/arm/st/f4/stm32f4.dtsi:416 */
			status = "okay";                /* in zephyr/boards/st/nucleo_f401re/nucleo_f401re.dts:178 */

			/* node '/soc/timers@40000000/pwm' defined in zephyr/dts/arm/st/f4/stm32f4.dtsi:419 */
			pwm2: pwm {
				compatible = "st,stm32-pwm";   /* in zephyr/dts/arm/st/f4/stm32f4.dtsi:420 */
				#pwm-cells = < 0x3 >;          /* in zephyr/dts/arm/st/f4/stm32f4.dtsi:422 */
				status = "okay";               /* in zephyr/boards/st/nucleo_f401re/nucleo_f401re.dts:181 */
				pinctrl-0 = < &tim2_ch1_pa5 >; /* in zephyr/boards/st/nucleo_f401re/nucleo_f401re.dts:182 */
				pinctrl-names = "default";     /* in zephyr/boards/st/nucleo_f401re/nucleo_f401re.dts:183 */
				phandle = < 0x26 >;            /* in zephyr/boards/st/nucleo_f401re/nucleo_f401re.dts:40 */
			};

			/* node '/soc/timers@40000000/counter' defined in zephyr/dts/arm/st/f4/stm32f4.dtsi:425 */
			counter {
				compatible = "st,stm32-counter"; /* in zephyr/dts/arm/st/f4/stm32f4.dtsi:426 */
				status = "disabled";             /* in zephyr/dts/arm/st/f4/stm32f4.dtsi:427 */
			};

			/* node '/soc/timers@40000000/qdec' defined in zephyr/dts/arm/st/f4/stm32f4.dtsi:430 */
			qdec {
				compatible = "st,stm32-qdec";    /* in zephyr/dts/arm/st/f4/stm32f4.dtsi:431 */
				st,input-filter-level = < 0x0 >; /* in zephyr/dts/arm/st/f4/stm32f4.dtsi:432 */
				status = "disabled";             /* in zephyr/dts/arm/st/f4/stm32f4.dtsi:433 */
			};
		};

		/* node '/soc/timers@40000400' defined in zephyr/dts/arm/st/f4/stm32f4.dtsi:437 */
		timers3: timers@40000400 {
			compatible = "st,stm32-timers"; /* in zephyr/dts/arm/st/f4/stm32f4.dtsi:438 */
			reg = < 0x40000400 0x400 >;     /* in zephyr/dts/arm/st/f4/stm32f4.dtsi:439 */
			clocks = < &rcc 0x40 0x2 >,
			         < &rcc 0x15 0xff >;    /* in zephyr/dts/arm/st/f4/stm32f4.dtsi:440 */
			resets = < &rctl 0x401 >;       /* in zephyr/dts/arm/st/f4/stm32f4.dtsi:442 */
			interrupts = < 0x1d 0x0 >;      /* in zephyr/dts/arm/st/f4/stm32f4.dtsi:443 */
			interrupt-names = "global";     /* in zephyr/dts/arm/st/f4/stm32f4.dtsi:444 */
			st,prescaler = < 0x0 >;         /* in zephyr/dts/arm/st/f4/stm32f4.dtsi:445 */
			status = "disabled";            /* in zephyr/dts/arm/st/f4/stm32f4.dtsi:446 */

			/* node '/soc/timers@40000400/pwm' defined in zephyr/dts/arm/st/f4/stm32f4.dtsi:448 */
			pwm {
				compatible = "st,stm32-pwm"; /* in zephyr/dts/arm/st/f4/stm32f4.dtsi:449 */
				status = "disabled";         /* in zephyr/dts/arm/st/f4/stm32f4.dtsi:450 */
				#pwm-cells = < 0x3 >;        /* in zephyr/dts/arm/st/f4/stm32f4.dtsi:451 */
			};

			/* node '/soc/timers@40000400/counter' defined in zephyr/dts/arm/st/f4/stm32f4.dtsi:454 */
			counter {
				compatible = "st,stm32-counter"; /* in zephyr/dts/arm/st/f4/stm32f4.dtsi:455 */
				status = "disabled";             /* in zephyr/dts/arm/st/f4/stm32f4.dtsi:456 */
			};

			/* node '/soc/timers@40000400/qdec' defined in zephyr/dts/arm/st/f4/stm32f4.dtsi:459 */
			qdec {
				compatible = "st,stm32-qdec";    /* in zephyr/dts/arm/st/f4/stm32f4.dtsi:460 */
				st,input-filter-level = < 0x0 >; /* in zephyr/dts/arm/st/f4/stm32f4.dtsi:461 */
				status = "disabled";             /* in zephyr/dts/arm/st/f4/stm32f4.dtsi:462 */
			};
		};

		/* node '/soc/timers@40000800' defined in zephyr/dts/arm/st/f4/stm32f4.dtsi:466 */
		timers4: timers@40000800 {
			compatible = "st,stm32-timers"; /* in zephyr/dts/arm/st/f4/stm32f4.dtsi:467 */
			reg = < 0x40000800 0x400 >;     /* in zephyr/dts/arm/st/f4/stm32f4.dtsi:468 */
			clocks = < &rcc 0x40 0x4 >,
			         < &rcc 0x15 0xff >;    /* in zephyr/dts/arm/st/f4/stm32f4.dtsi:469 */
			resets = < &rctl 0x402 >;       /* in zephyr/dts/arm/st/f4/stm32f4.dtsi:471 */
			interrupts = < 0x1e 0x0 >;      /* in zephyr/dts/arm/st/f4/stm32f4.dtsi:472 */
			interrupt-names = "global";     /* in zephyr/dts/arm/st/f4/stm32f4.dtsi:473 */
			st,prescaler = < 0x0 >;         /* in zephyr/dts/arm/st/f4/stm32f4.dtsi:474 */
			status = "disabled";            /* in zephyr/dts/arm/st/f4/stm32f4.dtsi:475 */

			/* node '/soc/timers@40000800/pwm' defined in zephyr/dts/arm/st/f4/stm32f4.dtsi:477 */
			pwm {
				compatible = "st,stm32-pwm"; /* in zephyr/dts/arm/st/f4/stm32f4.dtsi:478 */
				status = "disabled";         /* in zephyr/dts/arm/st/f4/stm32f4.dtsi:479 */
				#pwm-cells = < 0x3 >;        /* in zephyr/dts/arm/st/f4/stm32f4.dtsi:480 */
			};

			/* node '/soc/timers@40000800/counter' defined in zephyr/dts/arm/st/f4/stm32f4.dtsi:483 */
			counter {
				compatible = "st,stm32-counter"; /* in zephyr/dts/arm/st/f4/stm32f4.dtsi:484 */
				status = "disabled";             /* in zephyr/dts/arm/st/f4/stm32f4.dtsi:485 */
			};

			/* node '/soc/timers@40000800/qdec' defined in zephyr/dts/arm/st/f4/stm32f4.dtsi:488 */
			qdec {
				compatible = "st,stm32-qdec";    /* in zephyr/dts/arm/st/f4/stm32f4.dtsi:489 */
				st,input-filter-level = < 0x0 >; /* in zephyr/dts/arm/st/f4/stm32f4.dtsi:490 */
				status = "disabled";             /* in zephyr/dts/arm/st/f4/stm32f4.dtsi:491 */
			};
		};

		/* node '/soc/timers@40000c00' defined in zephyr/dts/arm/st/f4/stm32f4.dtsi:495 */
		timers5: timers@40000c00 {
			compatible = "st,stm32-timers"; /* in zephyr/dts/arm/st/f4/stm32f4.dtsi:496 */
			reg = < 0x40000c00 0x400 >;     /* in zephyr/dts/arm/st/f4/stm32f4.dtsi:497 */
			clocks = < &rcc 0x40 0x8 >,
			         < &rcc 0x15 0xff >;    /* in zephyr/dts/arm/st/f4/stm32f4.dtsi:498 */
			resets = < &rctl 0x403 >;       /* in zephyr/dts/arm/st/f4/stm32f4.dtsi:500 */
			interrupts = < 0x32 0x0 >;      /* in zephyr/dts/arm/st/f4/stm32f4.dtsi:501 */
			interrupt-names = "global";     /* in zephyr/dts/arm/st/f4/stm32f4.dtsi:502 */
			st,prescaler = < 0x0 >;         /* in zephyr/dts/arm/st/f4/stm32f4.dtsi:503 */
			status = "disabled";            /* in zephyr/dts/arm/st/f4/stm32f4.dtsi:504 */

			/* node '/soc/timers@40000c00/pwm' defined in zephyr/dts/arm/st/f4/stm32f4.dtsi:506 */
			pwm {
				compatible = "st,stm32-pwm"; /* in zephyr/dts/arm/st/f4/stm32f4.dtsi:507 */
				status = "disabled";         /* in zephyr/dts/arm/st/f4/stm32f4.dtsi:508 */
				#pwm-cells = < 0x3 >;        /* in zephyr/dts/arm/st/f4/stm32f4.dtsi:509 */
			};

			/* node '/soc/timers@40000c00/counter' defined in zephyr/dts/arm/st/f4/stm32f4.dtsi:512 */
			counter {
				compatible = "st,stm32-counter"; /* in zephyr/dts/arm/st/f4/stm32f4.dtsi:513 */
				status = "disabled";             /* in zephyr/dts/arm/st/f4/stm32f4.dtsi:514 */
			};

			/* node '/soc/timers@40000c00/qdec' defined in zephyr/dts/arm/st/f4/stm32f4.dtsi:517 */
			qdec {
				compatible = "st,stm32-qdec";    /* in zephyr/dts/arm/st/f4/stm32f4.dtsi:518 */
				st,input-filter-level = < 0x0 >; /* in zephyr/dts/arm/st/f4/stm32f4.dtsi:519 */
				status = "disabled";             /* in zephyr/dts/arm/st/f4/stm32f4.dtsi:520 */
			};
		};

		/* node '/soc/timers@40014000' defined in zephyr/dts/arm/st/f4/stm32f4.dtsi:524 */
		timers9: timers@40014000 {
			compatible = "st,stm32-timers"; /* in zephyr/dts/arm/st/f4/stm32f4.dtsi:525 */
			reg = < 0x40014000 0x400 >;     /* in zephyr/dts/arm/st/f4/stm32f4.dtsi:526 */
			clocks = < &rcc 0x44 0x10000 >,
			         < &rcc 0x16 0xff >;    /* in zephyr/dts/arm/st/f4/stm32f4.dtsi:527 */
			resets = < &rctl 0x490 >;       /* in zephyr/dts/arm/st/f4/stm32f4.dtsi:529 */
			interrupts = < 0x18 0x0 >;      /* in zephyr/dts/arm/st/f4/stm32f4.dtsi:530 */
			interrupt-names = "global";     /* in zephyr/dts/arm/st/f4/stm32f4.dtsi:531 */
			st,prescaler = < 0x0 >;         /* in zephyr/dts/arm/st/f4/stm32f4.dtsi:532 */
			status = "disabled";            /* in zephyr/dts/arm/st/f4/stm32f4.dtsi:533 */

			/* node '/soc/timers@40014000/pwm' defined in zephyr/dts/arm/st/f4/stm32f4.dtsi:535 */
			pwm {
				compatible = "st,stm32-pwm"; /* in zephyr/dts/arm/st/f4/stm32f4.dtsi:536 */
				status = "disabled";         /* in zephyr/dts/arm/st/f4/stm32f4.dtsi:537 */
				#pwm-cells = < 0x3 >;        /* in zephyr/dts/arm/st/f4/stm32f4.dtsi:538 */
			};

			/* node '/soc/timers@40014000/counter' defined in zephyr/dts/arm/st/f4/stm32f4.dtsi:541 */
			counter {
				compatible = "st,stm32-counter"; /* in zephyr/dts/arm/st/f4/stm32f4.dtsi:542 */
				status = "disabled";             /* in zephyr/dts/arm/st/f4/stm32f4.dtsi:543 */
			};
		};

		/* node '/soc/timers@40014400' defined in zephyr/dts/arm/st/f4/stm32f4.dtsi:547 */
		timers10: timers@40014400 {
			compatible = "st,stm32-timers"; /* in zephyr/dts/arm/st/f4/stm32f4.dtsi:548 */
			reg = < 0x40014400 0x400 >;     /* in zephyr/dts/arm/st/f4/stm32f4.dtsi:549 */
			clocks = < &rcc 0x44 0x20000 >,
			         < &rcc 0x16 0xff >;    /* in zephyr/dts/arm/st/f4/stm32f4.dtsi:550 */
			resets = < &rctl 0x491 >;       /* in zephyr/dts/arm/st/f4/stm32f4.dtsi:552 */
			interrupts = < 0x19 0x0 >;      /* in zephyr/dts/arm/st/f4/stm32f4.dtsi:553 */
			interrupt-names = "global";     /* in zephyr/dts/arm/st/f4/stm32f4.dtsi:554 */
			st,prescaler = < 0x0 >;         /* in zephyr/dts/arm/st/f4/stm32f4.dtsi:555 */
			status = "disabled";            /* in zephyr/dts/arm/st/f4/stm32f4.dtsi:556 */

			/* node '/soc/timers@40014400/pwm' defined in zephyr/dts/arm/st/f4/stm32f4.dtsi:558 */
			pwm {
				compatible = "st,stm32-pwm"; /* in zephyr/dts/arm/st/f4/stm32f4.dtsi:559 */
				status = "disabled";         /* in zephyr/dts/arm/st/f4/stm32f4.dtsi:560 */
				#pwm-cells = < 0x3 >;        /* in zephyr/dts/arm/st/f4/stm32f4.dtsi:561 */
			};

			/* node '/soc/timers@40014400/counter' defined in zephyr/dts/arm/st/f4/stm32f4.dtsi:564 */
			counter {
				compatible = "st,stm32-counter"; /* in zephyr/dts/arm/st/f4/stm32f4.dtsi:565 */
				status = "disabled";             /* in zephyr/dts/arm/st/f4/stm32f4.dtsi:566 */
			};
		};

		/* node '/soc/timers@40014800' defined in zephyr/dts/arm/st/f4/stm32f4.dtsi:570 */
		timers11: timers@40014800 {
			compatible = "st,stm32-timers"; /* in zephyr/dts/arm/st/f4/stm32f4.dtsi:571 */
			reg = < 0x40014800 0x400 >;     /* in zephyr/dts/arm/st/f4/stm32f4.dtsi:572 */
			clocks = < &rcc 0x44 0x40000 >,
			         < &rcc 0x16 0xff >;    /* in zephyr/dts/arm/st/f4/stm32f4.dtsi:573 */
			resets = < &rctl 0x492 >;       /* in zephyr/dts/arm/st/f4/stm32f4.dtsi:575 */
			interrupts = < 0x1a 0x0 >;      /* in zephyr/dts/arm/st/f4/stm32f4.dtsi:576 */
			interrupt-names = "global";     /* in zephyr/dts/arm/st/f4/stm32f4.dtsi:577 */
			st,prescaler = < 0x0 >;         /* in zephyr/dts/arm/st/f4/stm32f4.dtsi:578 */
			status = "disabled";            /* in zephyr/dts/arm/st/f4/stm32f4.dtsi:579 */

			/* node '/soc/timers@40014800/pwm' defined in zephyr/dts/arm/st/f4/stm32f4.dtsi:581 */
			pwm {
				compatible = "st,stm32-pwm"; /* in zephyr/dts/arm/st/f4/stm32f4.dtsi:582 */
				status = "disabled";         /* in zephyr/dts/arm/st/f4/stm32f4.dtsi:583 */
				#pwm-cells = < 0x3 >;        /* in zephyr/dts/arm/st/f4/stm32f4.dtsi:584 */
			};

			/* node '/soc/timers@40014800/counter' defined in zephyr/dts/arm/st/f4/stm32f4.dtsi:587 */
			counter {
				compatible = "st,stm32-counter"; /* in zephyr/dts/arm/st/f4/stm32f4.dtsi:588 */
				status = "disabled";             /* in zephyr/dts/arm/st/f4/stm32f4.dtsi:589 */
			};
		};

		/* node '/soc/rtc@40002800' defined in zephyr/dts/arm/st/f4/stm32f4.dtsi:593 */
		rtc: rtc@40002800 {
			compatible = "st,stm32-rtc";       /* in zephyr/dts/arm/st/f4/stm32f4.dtsi:594 */
			reg = < 0x40002800 0x400 >;        /* in zephyr/dts/arm/st/f4/stm32f4.dtsi:595 */
			interrupts = < 0x29 0x0 >;         /* in zephyr/dts/arm/st/f4/stm32f4.dtsi:596 */
			prescaler = < 0x8000 >;            /* in zephyr/dts/arm/st/f4/stm32f4.dtsi:598 */
			alarms-count = < 0x2 >;            /* in zephyr/dts/arm/st/f4/stm32f4.dtsi:599 */
			alrm-exti-line = < 0x11 >;         /* in zephyr/dts/arm/st/f4/stm32f4.dtsi:600 */
			clocks = < &rcc 0x40 0x10000000 >,
			         < &rcc 0x3 0x2280070 >;   /* in zephyr/boards/st/nucleo_f401re/nucleo_f401re.dts:188 */
			status = "okay";                   /* in zephyr/boards/st/nucleo_f401re/nucleo_f401re.dts:190 */

			/* node '/soc/rtc@40002800/backup_regs' defined in zephyr/dts/arm/st/f4/stm32f4.dtsi:603 */
			bbram: backup_regs {
				compatible = "st,stm32-bbram"; /* in zephyr/dts/arm/st/f4/stm32f4.dtsi:604 */
				st,backup-regs = < 0x14 >;     /* in zephyr/dts/arm/st/f4/stm32f4.dtsi:605 */
				status = "disabled";           /* in zephyr/dts/arm/st/f4/stm32f4.dtsi:606 */
			};
		};

		/* node '/soc/adc@40012000' defined in zephyr/dts/arm/st/f4/stm32f4.dtsi:610 */
		adc1: adc@40012000 {
			compatible = "st,stm32f4-adc",
			             "st,stm32-adc";                                 /* in zephyr/dts/arm/st/f4/stm32f4.dtsi:611 */
			reg = < 0x40012000 0x400 >;                                  /* in zephyr/dts/arm/st/f4/stm32f4.dtsi:612 */
			clocks = < &rcc 0x44 0x100 >;                                /* in zephyr/dts/arm/st/f4/stm32f4.dtsi:613 */
			clock-names = "adcx";                                        /* in zephyr/dts/arm/st/f4/stm32f4.dtsi:614 */
			interrupts = < 0x12 0x0 >;                                   /* in zephyr/dts/arm/st/f4/stm32f4.dtsi:615 */
			#io-channel-cells = < 0x1 >;                                 /* in zephyr/dts/arm/st/f4/stm32f4.dtsi:616 */
			st,adc-resolutions = < 0xc 0xa 0x8 0x6 >;                    /* in zephyr/dts/arm/st/f4/stm32f4.dtsi:617 */
			sampling-times = < 0x3 0xf 0x1c 0x38 0x54 0x70 0x90 0x1e0 >; /* in zephyr/dts/arm/st/f4/stm32f4.dtsi:618 */
			st,adc-sequencer = "programmable";                           /* in zephyr/dts/arm/st/f4/stm32f4.dtsi:620 */
			st,adc-oversampler = "none";                                 /* in zephyr/dts/arm/st/f4/stm32f4.dtsi:621 */
			st,adc-internal-regulator = "none";                          /* in zephyr/dts/arm/st/f4/stm32f4.dtsi:622 */
			st,adc-has-injected-support;                                 /* in zephyr/dts/arm/st/f4/stm32f4.dtsi:623 */
			pinctrl-0 = < &adc1_in0_pa0 >;                               /* in zephyr/boards/st/nucleo_f401re/nucleo_f401re.dts:194 */
			pinctrl-names = "default";                                   /* in zephyr/boards/st/nucleo_f401re/nucleo_f401re.dts:195 */
			st,adc-clock-source = "SYNC";                                /* in zephyr/boards/st/nucleo_f401re/nucleo_f401re.dts:196 */
			st,adc-prescaler = < 0x2 >;                                  /* in zephyr/boards/st/nucleo_f401re/nucleo_f401re.dts:197 */
			status = "okay";                                             /* in zephyr/boards/st/nucleo_f401re/nucleo_f401re.dts:198 */
			phandle = < 0x1f >;                                          /* in zephyr/dts/arm/st/f4/stm32f4.dtsi:680 */
		};

		/* node '/soc/dma@40026000' defined in zephyr/dts/arm/st/f4/stm32f4.dtsi:627 */
		dma1: dma@40026000 {
			compatible = "st,stm32-dma-v1";                                                      /* in zephyr/dts/arm/st/f4/stm32f4.dtsi:628 */
			#dma-cells = < 0x4 >;                                                                /* in zephyr/dts/arm/st/f4/stm32f4.dtsi:629 */
			reg = < 0x40026000 0x400 >;                                                          /* in zephyr/dts/arm/st/f4/stm32f4.dtsi:630 */
			interrupts = < 0xb 0x0 0xc 0x0 0xd 0x0 0xe 0x0 0xf 0x0 0x10 0x0 0x11 0x0 0x2f 0x0 >; /* in zephyr/dts/arm/st/f4/stm32f4.dtsi:631 */
			clocks = < &rcc 0x30 0x200000 >;                                                     /* in zephyr/dts/arm/st/f4/stm32f4.dtsi:632 */
			status = "disabled";                                                                 /* in zephyr/dts/arm/st/f4/stm32f4.dtsi:633 */
			phandle = < 0x1a >;                                                                  /* in zephyr/dts/arm/st/f4/stm32f401.dtsi:61 */
		};

		/* node '/soc/dma@40026400' defined in zephyr/dts/arm/st/f4/stm32f4.dtsi:636 */
		dma2: dma@40026400 {
			compatible = "st,stm32-dma-v1";                                                           /* in zephyr/dts/arm/st/f4/stm32f4.dtsi:637 */
			#dma-cells = < 0x4 >;                                                                     /* in zephyr/dts/arm/st/f4/stm32f4.dtsi:638 */
			reg = < 0x40026400 0x400 >;                                                               /* in zephyr/dts/arm/st/f4/stm32f4.dtsi:639 */
			interrupts = < 0x38 0x0 0x39 0x0 0x3a 0x0 0x3b 0x0 0x3c 0x0 0x44 0x0 0x45 0x0 0x46 0x0 >; /* in zephyr/dts/arm/st/f4/stm32f4.dtsi:640 */
			clocks = < &rcc 0x30 0x400000 >;                                                          /* in zephyr/dts/arm/st/f4/stm32f4.dtsi:641 */
			st,mem2mem;                                                                               /* in zephyr/dts/arm/st/f4/stm32f4.dtsi:642 */
			status = "disabled";                                                                      /* in zephyr/dts/arm/st/f4/stm32f4.dtsi:643 */
		};

		/* node '/soc/sdmmc@40012c00' defined in zephyr/dts/arm/st/f4/stm32f4.dtsi:646 */
		sdmmc1: sdmmc@40012c00 {
			compatible = "st,stm32-sdmmc"; /* in zephyr/dts/arm/st/f4/stm32f4.dtsi:647 */
			reg = < 0x40012c00 0x400 >;    /* in zephyr/dts/arm/st/f4/stm32f4.dtsi:648 */
			clocks = < &rcc 0x44 0x800 >,
			         < &rcc 0x7 0xff >;    /* in zephyr/dts/arm/st/f4/stm32f4.dtsi:649 */
			resets = < &rctl 0x48b >;      /* in zephyr/dts/arm/st/f4/stm32f4.dtsi:651 */
			interrupts = < 0x31 0x0 >;     /* in zephyr/dts/arm/st/f4/stm32f4.dtsi:652 */
			status = "disabled";           /* in zephyr/dts/arm/st/f4/stm32f4.dtsi:653 */
		};

		/* node '/soc/spi@40003800' defined in zephyr/dts/arm/st/f4/stm32f401.dtsi:21 */
		spi2: spi@40003800 {
			compatible = "st,stm32-spi";                                                   /* in zephyr/dts/arm/st/f4/stm32f401.dtsi:22 */
			#address-cells = < 0x1 >;                                                      /* in zephyr/dts/arm/st/f4/stm32f401.dtsi:23 */
			#size-cells = < 0x0 >;                                                         /* in zephyr/dts/arm/st/f4/stm32f401.dtsi:24 */
			reg = < 0x40003800 0x400 >;                                                    /* in zephyr/dts/arm/st/f4/stm32f401.dtsi:25 */
			clocks = < &rcc 0x40 0x4000 >;                                                 /* in zephyr/dts/arm/st/f4/stm32f401.dtsi:26 */
			interrupts = < 0x24 0x0 >;                                                     /* in zephyr/dts/arm/st/f4/stm32f401.dtsi:27 */
			st,spi-data-width = "limited-8-16-bit";                                        /* in zephyr/dts/arm/st/f4/stm32f401.dtsi:28 */
			pinctrl-0 = < &spi2_nss_pb12 &spi2_sck_pb13 &spi2_miso_pb14 &spi2_mosi_pb15 >; /* in zephyr/boards/st/nucleo_f401re/nucleo_f401re.dts:133 */
			pinctrl-names = "default";                                                     /* in zephyr/boards/st/nucleo_f401re/nucleo_f401re.dts:135 */
			status = "okay";                                                               /* in zephyr/boards/st/nucleo_f401re/nucleo_f401re.dts:136 */
		};

		/* node '/soc/spi@40003c00' defined in zephyr/dts/arm/st/f4/stm32f401.dtsi:32 */
		spi3: spi@40003c00 {
			compatible = "st,stm32-spi";            /* in zephyr/dts/arm/st/f4/stm32f401.dtsi:33 */
			#address-cells = < 0x1 >;               /* in zephyr/dts/arm/st/f4/stm32f401.dtsi:34 */
			#size-cells = < 0x0 >;                  /* in zephyr/dts/arm/st/f4/stm32f401.dtsi:35 */
			reg = < 0x40003c00 0x400 >;             /* in zephyr/dts/arm/st/f4/stm32f401.dtsi:36 */
			clocks = < &rcc 0x40 0x8000 >;          /* in zephyr/dts/arm/st/f4/stm32f401.dtsi:37 */
			interrupts = < 0x33 0x0 >;              /* in zephyr/dts/arm/st/f4/stm32f401.dtsi:38 */
			st,spi-data-width = "limited-8-16-bit"; /* in zephyr/dts/arm/st/f4/stm32f401.dtsi:39 */
			status = "disabled";                    /* in zephyr/dts/arm/st/f4/stm32f401.dtsi:40 */
		};

		/* node '/soc/spi@40013400' defined in zephyr/dts/arm/st/f4/stm32f401.dtsi:43 */
		spi4: spi@40013400 {
			compatible = "st,stm32-spi";            /* in zephyr/dts/arm/st/f4/stm32f401.dtsi:44 */
			#address-cells = < 0x1 >;               /* in zephyr/dts/arm/st/f4/stm32f401.dtsi:45 */
			#size-cells = < 0x0 >;                  /* in zephyr/dts/arm/st/f4/stm32f401.dtsi:46 */
			reg = < 0x40013400 0x400 >;             /* in zephyr/dts/arm/st/f4/stm32f401.dtsi:47 */
			clocks = < &rcc 0x44 0x2000 >;          /* in zephyr/dts/arm/st/f4/stm32f401.dtsi:48 */
			interrupts = < 0x54 0x0 >;              /* in zephyr/dts/arm/st/f4/stm32f401.dtsi:49 */
			st,spi-data-width = "limited-8-16-bit"; /* in zephyr/dts/arm/st/f4/stm32f401.dtsi:50 */
			status = "disabled";                    /* in zephyr/dts/arm/st/f4/stm32f401.dtsi:51 */
		};

		/* node '/soc/i2s@40003800' defined in zephyr/dts/arm/st/f4/stm32f401.dtsi:54 */
		i2s2: i2s@40003800 {
			compatible = "st,stm32-i2s";        /* in zephyr/dts/arm/st/f4/stm32f401.dtsi:55 */
			#address-cells = < 0x1 >;           /* in zephyr/dts/arm/st/f4/stm32f401.dtsi:56 */
			#size-cells = < 0x0 >;              /* in zephyr/dts/arm/st/f4/stm32f401.dtsi:57 */
			reg = < 0x40003800 0x400 >;         /* in zephyr/dts/arm/st/f4/stm32f401.dtsi:58 */
			clocks = < &rcc 0x40 0x4000 >;      /* in zephyr/dts/arm/st/f4/stm32f401.dtsi:59 */
			interrupts = < 0x24 0x0 >;          /* in zephyr/dts/arm/st/f4/stm32f401.dtsi:60 */
			dmas = < &dma1 0x4 0x0 0x400 0x3 >,
			       < &dma1 0x3 0x0 0x400 0x3 >; /* in zephyr/dts/arm/st/f4/stm32f401.dtsi:61 */
			dma-names = "tx",
			            "rx";                   /* in zephyr/dts/arm/st/f4/stm32f401.dtsi:63 */
			status = "disabled";                /* in zephyr/dts/arm/st/f4/stm32f401.dtsi:64 */
		};

		/* node '/soc/i2s@40003c00' defined in zephyr/dts/arm/st/f4/stm32f401.dtsi:67 */
		i2s3: i2s@40003c00 {
			compatible = "st,stm32-i2s";        /* in zephyr/dts/arm/st/f4/stm32f401.dtsi:68 */
			#address-cells = < 0x1 >;           /* in zephyr/dts/arm/st/f4/stm32f401.dtsi:69 */
			#size-cells = < 0x0 >;              /* in zephyr/dts/arm/st/f4/stm32f401.dtsi:70 */
			reg = < 0x40003c00 0x400 >;         /* in zephyr/dts/arm/st/f4/stm32f401.dtsi:71 */
			clocks = < &rcc 0x40 0x8000 >;      /* in zephyr/dts/arm/st/f4/stm32f401.dtsi:72 */
			interrupts = < 0x33 0x0 >;          /* in zephyr/dts/arm/st/f4/stm32f401.dtsi:73 */
			dmas = < &dma1 0x5 0x0 0x400 0x3 >,
			       < &dma1 0x0 0x0 0x400 0x3 >; /* in zephyr/dts/arm/st/f4/stm32f401.dtsi:74 */
			dma-names = "tx",
			            "rx";                   /* in zephyr/dts/arm/st/f4/stm32f401.dtsi:76 */
			status = "disabled";                /* in zephyr/dts/arm/st/f4/stm32f401.dtsi:77 */
		};
	};

	/* node '/cpus' defined in zephyr/dts/arm/st/f4/stm32f4.dtsi:30 */
	cpus {
		#address-cells = < 0x1 >; /* in zephyr/dts/arm/st/f4/stm32f4.dtsi:31 */
		#size-cells = < 0x0 >;    /* in zephyr/dts/arm/st/f4/stm32f4.dtsi:32 */

		/* node '/cpus/cpu@0' defined in zephyr/dts/arm/st/f4/stm32f4.dtsi:34 */
		cpu0: cpu@0 {
			device_type = "cpu";           /* in zephyr/dts/arm/st/f4/stm32f4.dtsi:35 */
			compatible = "arm,cortex-m4f"; /* in zephyr/dts/arm/st/f4/stm32f4.dtsi:36 */
			reg = < 0x0 >;                 /* in zephyr/dts/arm/st/f4/stm32f4.dtsi:37 */
			cpu-power-states = < &stop >;  /* in zephyr/dts/arm/st/f4/stm32f4.dtsi:38 */
		};

		/* node '/cpus/power-states' defined in zephyr/dts/arm/st/f4/stm32f4.dtsi:41 */
		power-states {

			/* node '/cpus/power-states/stop' defined in zephyr/dts/arm/st/f4/stm32f4.dtsi:42 */
			stop: stop {
				compatible = "zephyr,power-state";    /* in zephyr/dts/arm/st/f4/stm32f4.dtsi:43 */
				power-state-name = "suspend-to-idle"; /* in zephyr/dts/arm/st/f4/stm32f4.dtsi:44 */
				min-residency-us = < 0x190 >;         /* in zephyr/dts/arm/st/f4/stm32f4.dtsi:51 */
				exit-latency-us = < 0x12c >;          /* in zephyr/dts/arm/st/f4/stm32f4.dtsi:52 */
				phandle = < 0x1b >;                   /* in zephyr/dts/arm/st/f4/stm32f4.dtsi:38 */
			};
		};
	};

	/* node '/memory@20000000' defined in zephyr/dts/arm/st/f4/stm32f4.dtsi:57 */
	sram0: memory@20000000 {
		compatible = "zephyr,memory-region",
		             "mmio-sram";            /* in zephyr/dts/arm/st/f4/stm32f4.dtsi:58 */
		zephyr,memory-region = "SRAM0";      /* in zephyr/dts/arm/st/f4/stm32f4.dtsi:59 */
		reg = < 0x20000000 0x18000 >;        /* in zephyr/dts/arm/st/f4/stm32f401Xe.dtsi:11 */
	};

	/* node '/clocks' defined in zephyr/dts/arm/st/f4/stm32f4.dtsi:62 */
	clocks {

		/* node '/clocks/clk-hse' defined in zephyr/dts/arm/st/f4/stm32f4.dtsi:63 */
		clk_hse: clk-hse {
			#clock-cells = < 0x0 >;            /* in zephyr/dts/arm/st/f4/stm32f4.dtsi:64 */
			compatible = "st,stm32-hse-clock"; /* in zephyr/dts/arm/st/f4/stm32f4.dtsi:65 */
			hse-bypass;                        /* in zephyr/boards/st/nucleo_f401re/nucleo_f401re.dts:71 */
			clock-frequency = < 0x7a1200 >;    /* in zephyr/boards/st/nucleo_f401re/nucleo_f401re.dts:72 */
			status = "okay";                   /* in zephyr/boards/st/nucleo_f401re/nucleo_f401re.dts:73 */
			phandle = < 0x1c >;                /* in zephyr/boards/st/nucleo_f401re/nucleo_f401re.dts:81 */
		};

		/* node '/clocks/clk-hsi' defined in zephyr/dts/arm/st/f4/stm32f4.dtsi:69 */
		clk_hsi: clk-hsi {
			#clock-cells = < 0x0 >;         /* in zephyr/dts/arm/st/f4/stm32f4.dtsi:70 */
			compatible = "fixed-clock";     /* in zephyr/dts/arm/st/f4/stm32f4.dtsi:71 */
			clock-frequency = < 0xf42400 >; /* in zephyr/dts/arm/st/f4/stm32f4.dtsi:72 */
			status = "disabled";            /* in zephyr/dts/arm/st/f4/stm32f4.dtsi:73 */
		};

		/* node '/clocks/clk-lse' defined in zephyr/dts/arm/st/f4/stm32f4.dtsi:76 */
		clk_lse: clk-lse {
			#clock-cells = < 0x0 >;       /* in zephyr/dts/arm/st/f4/stm32f4.dtsi:77 */
			compatible = "fixed-clock";   /* in zephyr/dts/arm/st/f4/stm32f4.dtsi:78 */
			clock-frequency = < 0x8000 >; /* in zephyr/dts/arm/st/f4/stm32f4.dtsi:79 */
			status = "disabled";          /* in zephyr/dts/arm/st/f4/stm32f4.dtsi:80 */
		};

		/* node '/clocks/clk-lsi' defined in zephyr/dts/arm/st/f4/stm32f4.dtsi:83 */
		clk_lsi: clk-lsi {
			#clock-cells = < 0x0 >;       /* in zephyr/dts/arm/st/f4/stm32f4.dtsi:84 */
			compatible = "fixed-clock";   /* in zephyr/dts/arm/st/f4/stm32f4.dtsi:85 */
			clock-frequency = < 0x7d00 >; /* in zephyr/dts/arm/st/f4/stm32f4.dtsi:86 */
			status = "okay";              /* in zephyr/boards/st/nucleo_f401re/nucleo_f401re.dts:67 */
		};

		/* node '/clocks/pll' defined in zephyr/dts/arm/st/f4/stm32f4.dtsi:90 */
		pll: pll {
			#clock-cells = < 0x0 >;              /* in zephyr/dts/arm/st/f4/stm32f4.dtsi:91 */
			compatible = "st,stm32fx-pll-clock"; /* in zephyr/dts/arm/st/f4/stm32f4.dtsi:92 */
			div-m = < 0x8 >;                     /* in zephyr/boards/st/nucleo_f401re/nucleo_f401re.dts:77 */
			mul-n = < 0x150 >;                   /* in zephyr/boards/st/nucleo_f401re/nucleo_f401re.dts:78 */
			div-p = < 0x4 >;                     /* in zephyr/boards/st/nucleo_f401re/nucleo_f401re.dts:79 */
			div-q = < 0x7 >;                     /* in zephyr/boards/st/nucleo_f401re/nucleo_f401re.dts:80 */
			clocks = < &clk_hse >;               /* in zephyr/boards/st/nucleo_f401re/nucleo_f401re.dts:81 */
			status = "okay";                     /* in zephyr/boards/st/nucleo_f401re/nucleo_f401re.dts:82 */
			phandle = < 0x2 >;                   /* in zephyr/boards/st/nucleo_f401re/nucleo_f401re.dts:86 */
		};

		/* node '/clocks/plli2s' defined in zephyr/dts/arm/st/f4/stm32f401.dtsi:11 */
		plli2s: plli2s {
			#clock-cells = < 0x0 >;              /* in zephyr/dts/arm/st/f4/stm32f401.dtsi:12 */
			compatible = "st,stm32fx-pll-clock"; /* in zephyr/dts/arm/st/f4/stm32f401.dtsi:13 */
			status = "disabled";                 /* in zephyr/dts/arm/st/f4/stm32f401.dtsi:14 */
		};
	};

	/* node '/mcos' defined in zephyr/dts/arm/st/f4/stm32f4.dtsi:97 */
	mcos {

		/* node '/mcos/mco1' defined in zephyr/dts/arm/st/f4/stm32f4.dtsi:98 */
		mco1: mco1 {
			compatible = "st,stm32-clock-mco"; /* in zephyr/dts/arm/st/f4/stm32f4.dtsi:99 */
			clock-names = "clksel";            /* in zephyr/dts/arm/st/f4/stm32f4.dtsi:100 */
			status = "disabled";               /* in zephyr/dts/arm/st/f4/stm32f4.dtsi:101 */
		};

		/* node '/mcos/mco2' defined in zephyr/dts/arm/st/f4/stm32f4.dtsi:104 */
		mco2: mco2 {
			compatible = "st,stm32-clock-mco"; /* in zephyr/dts/arm/st/f4/stm32f4.dtsi:105 */
			clock-names = "clksel";            /* in zephyr/dts/arm/st/f4/stm32f4.dtsi:106 */
			status = "disabled";               /* in zephyr/dts/arm/st/f4/stm32f4.dtsi:107 */
		};
	};

	/* node '/power@40007000' defined in zephyr/dts/arm/st/f4/stm32f4.dtsi:657 */
	pwr: power@40007000 {
		compatible = "st,stm32-pwr"; /* in zephyr/dts/arm/st/f4/stm32f4.dtsi:658 */
		reg = < 0x40007000 0x400 >;  /* in zephyr/dts/arm/st/f4/stm32f4.dtsi:659 */
		status = "disabled";         /* in zephyr/dts/arm/st/f4/stm32f4.dtsi:660 */
		wkup-pins-nb = < 0x1 >;      /* in zephyr/dts/arm/st/f4/stm32f4.dtsi:662 */
		#address-cells = < 0x1 >;    /* in zephyr/dts/arm/st/f4/stm32f4.dtsi:664 */
		#size-cells = < 0x0 >;       /* in zephyr/dts/arm/st/f4/stm32f4.dtsi:665 */

		/* node '/power@40007000/wkup-pin@1' defined in zephyr/dts/arm/st/f4/stm32f4.dtsi:667 */
		wkup-pin@1 {
			reg = < 0x1 >;                   /* in zephyr/dts/arm/st/f4/stm32f4.dtsi:668 */
			wkup-gpios = < &gpioa 0x0 0x1 >; /* in zephyr/dts/arm/st/f4/stm32f4.dtsi:669 */
		};
	};

	/* node '/dietemp' defined in zephyr/dts/arm/st/f4/stm32f4.dtsi:673 */
	die_temp: dietemp {
		compatible = "st,stm32-temp-cal"; /* in zephyr/dts/arm/st/f4/stm32f4.dtsi:674 */
		nvmem-cells = < &ts_cal1_otp >,
		              < &ts_cal2_otp >;   /* in zephyr/dts/arm/st/f4/stm32f4.dtsi:675 */
		nvmem-cell-names = "TS_CAL1",
		                   "TS_CAL2";     /* in zephyr/dts/arm/st/f4/stm32f4.dtsi:676 */
		ts-cal1-temp = < 0x1e >;          /* in zephyr/dts/arm/st/f4/stm32f4.dtsi:677 */
		ts-cal2-temp = < 0x6e >;          /* in zephyr/dts/arm/st/f4/stm32f4.dtsi:678 */
		ts-cal-vrefanalog = < 0xce4 >;    /* in zephyr/dts/arm/st/f4/stm32f4.dtsi:679 */
		io-channels = < &adc1 0x10 >;     /* in zephyr/dts/arm/st/f4/stm32f4.dtsi:680 */
		status = "okay";                  /* in zephyr/boards/st/nucleo_f401re/nucleo_f401re.dts:202 */
	};

	/* node '/vref' defined in zephyr/dts/arm/st/f4/stm32f4.dtsi:684 */
	vref: vref {
		compatible = "st,stm32-vref";   /* in zephyr/dts/arm/st/f4/stm32f4.dtsi:685 */
		nvmem-cells = < &vrefint_otp >; /* in zephyr/dts/arm/st/f4/stm32f4.dtsi:686 */
		vrefint-cal-mv = < 0xce4 >;     /* in zephyr/dts/arm/st/f4/stm32f4.dtsi:687 */
		io-channels = < &adc1 0x11 >;   /* in zephyr/dts/arm/st/f4/stm32f4.dtsi:688 */
		status = "okay";                /* in zephyr/boards/st/nucleo_f401re/nucleo_f401re.dts:210 */
	};

	/* node '/vbat' defined in zephyr/dts/arm/st/f4/stm32f4.dtsi:692 */
	vbat: vbat {
		compatible = "st,stm32-vbat"; /* in zephyr/dts/arm/st/f4/stm32f4.dtsi:693 */
		ratio = < 0x4 >;              /* in zephyr/dts/arm/st/f4/stm32f4.dtsi:694 */
		io-channels = < &adc1 0x12 >; /* in zephyr/dts/arm/st/f4/stm32f4.dtsi:695 */
		status = "okay";              /* in zephyr/boards/st/nucleo_f401re/nucleo_f401re.dts:214 */
	};

	/* node '/otgfs_phy' defined in zephyr/dts/arm/st/f4/stm32f4.dtsi:699 */
	otgfs_phy: otgfs_phy {
		compatible = "usb-nop-xceiv"; /* in zephyr/dts/arm/st/f4/stm32f4.dtsi:700 */
		#phy-cells = < 0x0 >;         /* in zephyr/dts/arm/st/f4/stm32f4.dtsi:701 */
		phandle = < 0x13 >;           /* in zephyr/dts/arm/st/f4/stm32f4.dtsi:373 */
	};

	/* node '/smbus1' defined in zephyr/dts/arm/st/f4/stm32f4.dtsi:704 */
	smbus1: smbus1 {
		compatible = "st,stm32-smbus"; /* in zephyr/dts/arm/st/f4/stm32f4.dtsi:705 */
		#address-cells = < 0x1 >;      /* in zephyr/dts/arm/st/f4/stm32f4.dtsi:706 */
		#size-cells = < 0x0 >;         /* in zephyr/dts/arm/st/f4/stm32f4.dtsi:707 */
		i2c = < &i2c1 >;               /* in zephyr/dts/arm/st/f4/stm32f4.dtsi:708 */
		status = "disabled";           /* in zephyr/dts/arm/st/f4/stm32f4.dtsi:709 */
	};

	/* node '/smbus2' defined in zephyr/dts/arm/st/f4/stm32f4.dtsi:712 */
	smbus2: smbus2 {
		compatible = "st,stm32-smbus"; /* in zephyr/dts/arm/st/f4/stm32f4.dtsi:713 */
		#address-cells = < 0x1 >;      /* in zephyr/dts/arm/st/f4/stm32f4.dtsi:714 */
		#size-cells = < 0x0 >;         /* in zephyr/dts/arm/st/f4/stm32f4.dtsi:715 */
		i2c = < &i2c2 >;               /* in zephyr/dts/arm/st/f4/stm32f4.dtsi:716 */
		status = "disabled";           /* in zephyr/dts/arm/st/f4/stm32f4.dtsi:717 */
	};

	/* node '/smbus3' defined in zephyr/dts/arm/st/f4/stm32f4.dtsi:720 */
	smbus3: smbus3 {
		compatible = "st,stm32-smbus"; /* in zephyr/dts/arm/st/f4/stm32f4.dtsi:721 */
		#address-cells = < 0x1 >;      /* in zephyr/dts/arm/st/f4/stm32f4.dtsi:722 */
		#size-cells = < 0x0 >;         /* in zephyr/dts/arm/st/f4/stm32f4.dtsi:723 */
		i2c = < &i2c3 >;               /* in zephyr/dts/arm/st/f4/stm32f4.dtsi:724 */
		status = "disabled";           /* in zephyr/dts/arm/st/f4/stm32f4.dtsi:725 */
	};

	/* node '/connector' defined in zephyr/boards/st/nucleo_f401re/arduino_r3_connector.dtsi:10 */
	arduino_header: connector {
		compatible = "arduino-header-r3";          /* in zephyr/boards/st/nucleo_f401re/arduino_r3_connector.dtsi:11 */
		#gpio-cells = < 0x2 >;                     /* in zephyr/boards/st/nucleo_f401re/arduino_r3_connector.dtsi:12 */
		gpio-map-mask = < 0xffffffff 0xffffffc0 >; /* in zephyr/boards/st/nucleo_f401re/arduino_r3_connector.dtsi:13 */
		gpio-map-pass-thru = < 0x0 0x3f >;         /* in zephyr/boards/st/nucleo_f401re/arduino_r3_connector.dtsi:14 */
		gpio-map = < 0x0 0x0 &gpioa 0x0 0x0 >,
		           < 0x1 0x0 &gpioa 0x1 0x0 >,
		           < 0x2 0x0 &gpioa 0x4 0x0 >,
		           < 0x3 0x0 &gpiob 0x0 0x0 >,
		           < 0x4 0x0 &gpioc 0x1 0x0 >,
		           < 0x5 0x0 &gpioc 0x0 0x0 >,
		           < 0x6 0x0 &gpioa 0x3 0x0 >,
		           < 0x7 0x0 &gpioa 0x2 0x0 >,
		           < 0x8 0x0 &gpioa 0xa 0x0 >,
		           < 0x9 0x0 &gpiob 0x3 0x0 >,
		           < 0xa 0x0 &gpiob 0x5 0x0 >,
		           < 0xb 0x0 &gpiob 0x4 0x0 >,
		           < 0xc 0x0 &gpiob 0xa 0x0 >,
		           < 0xd 0x0 &gpioa 0x8 0x0 >,
		           < 0xe 0x0 &gpioa 0x9 0x0 >,
		           < 0xf 0x0 &gpioc 0x7 0x0 >,
		           < 0x10 0x0 &gpiob 0x6 0x0 >,
		           < 0x11 0x0 &gpioa 0x7 0x0 >,
		           < 0x12 0x0 &gpioa 0x6 0x0 >,
		           < 0x13 0x0 &gpioa 0x5 0x0 >,
		           < 0x14 0x0 &gpiob 0x9 0x0 >,
		           < 0x15 0x0 &gpiob 0x8 0x0 >;    /* in zephyr/boards/st/nucleo_f401re/arduino_r3_connector.dtsi:15 */
	};

	/* node '/st-morpho-header' defined in zephyr/boards/st/nucleo_f401re/st_morpho_connector.dtsi:10 */
	st_morpho_header: st-morpho-header {
		compatible = "st-morpho-header";        /* in zephyr/boards/st/nucleo_f401re/st_morpho_connector.dtsi:11 */
		#gpio-cells = < 0x2 >;                  /* in zephyr/boards/st/nucleo_f401re/st_morpho_connector.dtsi:12 */
		gpio-map-mask = < 0xff 0x0 >;           /* in zephyr/boards/st/nucleo_f401re/st_morpho_connector.dtsi:13 */
		gpio-map-pass-thru = < 0x0 0x7f >;      /* in zephyr/boards/st/nucleo_f401re/st_morpho_connector.dtsi:14 */
		gpio-map = < 0x0 0x0 &gpioc 0xa 0x0 >,
		           < 0x1 0x0 &gpioc 0xb 0x0 >,
		           < 0x2 0x0 &gpioc 0xc 0x0 >,
		           < 0x3 0x0 &gpiod 0x2 0x0 >,
		           < 0xc 0x0 &gpioa 0xd 0x0 >,
		           < 0xe 0x0 &gpioa 0xe 0x0 >,
		           < 0x10 0x0 &gpioa 0xf 0x0 >,
		           < 0x14 0x0 &gpiob 0x7 0x0 >,
		           < 0x16 0x0 &gpioc 0xd 0x0 >,
		           < 0x18 0x0 &gpioc 0xe 0x0 >,
		           < 0x1a 0x0 &gpioc 0xf 0x0 >,
		           < 0x1b 0x0 &gpioa 0x0 0x0 >,
		           < 0x1c 0x0 &gpioh 0x0 0x0 >,
		           < 0x1d 0x0 &gpioa 0x1 0x0 >,
		           < 0x1e 0x0 &gpioh 0x1 0x0 >,
		           < 0x1f 0x0 &gpioa 0x4 0x0 >,
		           < 0x21 0x0 &gpiob 0x0 0x0 >,
		           < 0x22 0x0 &gpioc 0x2 0x0 >,
		           < 0x23 0x0 &gpioc 0x1 0x0 >,
		           < 0x24 0x0 &gpioc 0x3 0x0 >,
		           < 0x25 0x0 &gpioc 0x0 0x0 >,
		           < 0x48 0x0 &gpioc 0x9 0x0 >,
		           < 0x49 0x0 &gpioc 0x8 0x0 >,
		           < 0x4a 0x0 &gpiob 0x8 0x0 >,
		           < 0x4b 0x0 &gpioc 0x6 0x0 >,
		           < 0x4c 0x0 &gpiob 0x9 0x0 >,
		           < 0x4d 0x0 &gpioc 0x5 0x0 >,
		           < 0x52 0x0 &gpioa 0x5 0x0 >,
		           < 0x53 0x0 &gpioa 0xc 0x0 >,
		           < 0x54 0x0 &gpioa 0x6 0x0 >,
		           < 0x55 0x0 &gpioa 0xb 0x0 >,
		           < 0x56 0x0 &gpioa 0x7 0x0 >,
		           < 0x57 0x0 &gpiob 0xc 0x0 >,
		           < 0x58 0x0 &gpiob 0x6 0x0 >,
		           < 0x5a 0x0 &gpioc 0x7 0x0 >,
		           < 0x5c 0x0 &gpioa 0x9 0x0 >,
		           < 0x5d 0x0 &gpiob 0x2 0x0 >,
		           < 0x5e 0x0 &gpioa 0x8 0x0 >,
		           < 0x5f 0x0 &gpiob 0x1 0x0 >,
		           < 0x60 0x0 &gpiob 0xa 0x0 >,
		           < 0x61 0x0 &gpiob 0xf 0x0 >,
		           < 0x62 0x0 &gpiob 0x4 0x0 >,
		           < 0x63 0x0 &gpiob 0xe 0x0 >,
		           < 0x64 0x0 &gpiob 0x5 0x0 >,
		           < 0x65 0x0 &gpiob 0xd 0x0 >,
		           < 0x66 0x0 &gpiob 0x3 0x0 >,
		           < 0x68 0x0 &gpioa 0xa 0x0 >,
		           < 0x69 0x0 &gpioc 0x4 0x0 >,
		           < 0x6a 0x0 &gpioa 0x2 0x0 >,
		           < 0x6c 0x0 &gpioa 0x3 0x0 >; /* in zephyr/boards/st/nucleo_f401re/st_morpho_connector.dtsi:15 */
	};

	/* node '/leds' defined in zephyr/boards/st/nucleo_f401re/nucleo_f401re.dts:27 */
	leds: leds {
		compatible = "gpio-leds"; /* in zephyr/boards/st/nucleo_f401re/nucleo_f401re.dts:28 */

		/* node '/leds/led_2' defined in zephyr/boards/st/nucleo_f401re/nucleo_f401re.dts:30 */
		green_led_2: led_2 {
			gpios = < &gpioa 0x5 0x0 >; /* in zephyr/boards/st/nucleo_f401re/nucleo_f401re.dts:31 */
			label = "User LD2";         /* in zephyr/boards/st/nucleo_f401re/nucleo_f401re.dts:32 */
		};
	};

	/* node '/pwmleds' defined in zephyr/boards/st/nucleo_f401re/nucleo_f401re.dts:36 */
	pwmleds {
		compatible = "pwm-leds"; /* in zephyr/boards/st/nucleo_f401re/nucleo_f401re.dts:37 */

		/* node '/pwmleds/green_pwm_led' defined in zephyr/boards/st/nucleo_f401re/nucleo_f401re.dts:39 */
		green_pwm_led: green_pwm_led {
			pwms = < &pwm2 0x1 0x1312d00 0x0 >; /* in zephyr/boards/st/nucleo_f401re/nucleo_f401re.dts:40 */
		};
	};

	/* node '/gpio_keys' defined in zephyr/boards/st/nucleo_f401re/nucleo_f401re.dts:44 */
	gpio_keys {
		compatible = "gpio-keys"; /* in zephyr/boards/st/nucleo_f401re/nucleo_f401re.dts:45 */

		/* node '/gpio_keys/button' defined in zephyr/boards/st/nucleo_f401re/nucleo_f401re.dts:47 */
		user_button: button {
			label = "User";             /* in zephyr/boards/st/nucleo_f401re/nucleo_f401re.dts:48 */
			gpios = < &gpioc 0xd 0x1 >; /* in zephyr/boards/st/nucleo_f401re/nucleo_f401re.dts:49 */
			zephyr,code = < 0xb >;      /* in zephyr/boards/st/nucleo_f401re/nucleo_f401re.dts:50 */
		};
	};

	/* node '/connector_arduino_r3' defined in btr-shields/boards/extend/st/nucleo_f401re/arduino_r3_socket.dtsi:27 */
	nucleo_ard: connector_arduino_r3 {
		compatible = "socket,arduino-r3";          /* in btr-shields/boards/extend/st/nucleo_f401re/arduino_r3_socket.dtsi:28 */
		#gpio-cells = < 0x2 >;                     /* in btr-shields/boards/extend/st/nucleo_f401re/arduino_r3_socket.dtsi:29 */
		gpio-map-mask = < 0xffffffff 0xffffffc0 >; /* in btr-shields/boards/extend/st/nucleo_f401re/arduino_r3_socket.dtsi:30 */
		gpio-map-pass-thru = < 0x0 0x3f >;         /* in btr-shields/boards/extend/st/nucleo_f401re/arduino_r3_socket.dtsi:31 */
		gpio-map = < 0x0 0x0 &gpioa 0x0 0x0 >,
		           < 0x1 0x0 &gpioa 0x1 0x0 >,
		           < 0x2 0x0 &gpioa 0x4 0x0 >,
		           < 0x3 0x0 &gpiob 0x0 0x0 >,
		           < 0x4 0x0 &gpioc 0x1 0x0 >,
		           < 0x5 0x0 &gpioc 0x0 0x0 >,
		           < 0x6 0x0 &gpioa 0x3 0x0 >,
		           < 0x7 0x0 &gpioa 0x2 0x0 >,
		           < 0x8 0x0 &gpioa 0xa 0x0 >,
		           < 0x9 0x0 &gpiob 0x3 0x0 >,
		           < 0xa 0x0 &gpiob 0x5 0x0 >,
		           < 0xb 0x0 &gpiob 0x4 0x0 >,
		           < 0xc 0x0 &gpiob 0xa 0x0 >,
		           < 0xd 0x0 &gpioa 0x8 0x0 >,
		           < 0xe 0x0 &gpioa 0x9 0x0 >,
		           < 0xf 0x0 &gpioc 0x7 0x0 >,
		           < 0x10 0x0 &gpiob 0x6 0x0 >,
		           < 0x11 0x0 &gpioa 0x7 0x0 >,
		           < 0x12 0x0 &gpioa 0x6 0x0 >,
		           < 0x13 0x0 &gpioa 0x5 0x0 >,
		           < 0x14 0x0 &gpiob 0x9 0x0 >,
		           < 0x15 0x0 &gpiob 0x8 0x0 >;    /* in btr-shields/boards/extend/st/nucleo_f401re/arduino_r3_socket.dtsi:32 */
		socket,i2c = < &i2c1 >;                    /* in btr-shields/boards/extend/st/nucleo_f401re/arduino_r3_socket.dtsi:54 */
		socket,spi = < &spi1 >;                    /* in btr-shields/boards/extend/st/nucleo_f401re/arduino_r3_socket.dtsi:55 */
		socket,stackable;                          /* in btr-shields/boards/extend/st/nucleo_f401re/arduino_r3_socket.dtsi:56 */
	};
};
